[part 2 of 2: package /MICROSAR/Dcm_swc/ComponentTypes]
AUTOSAR XML (schema 00048)
package /MICROSAR/Dcm_swc/ComponentTypes
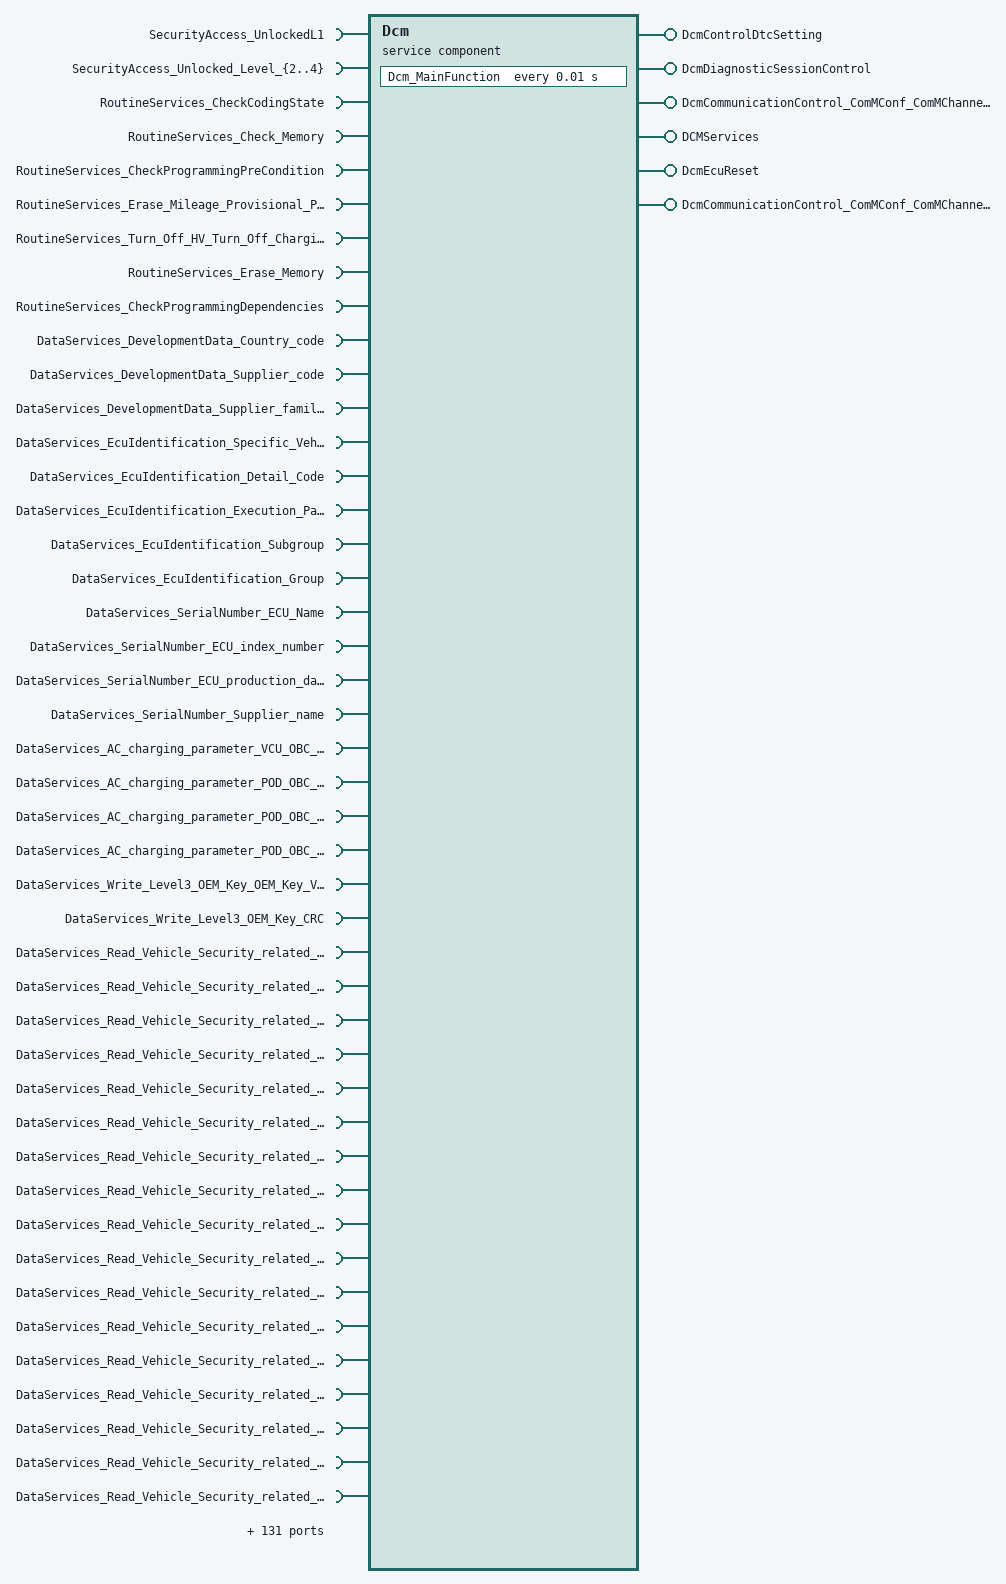
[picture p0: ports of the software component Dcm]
  service sw component type Dcm: category=SERVICE_COMPONENT
    4 x provide port:
      DcmControlDtcSetting: provided-interface=DcmControlDtcSetting
      DcmDiagnosticSessionControl: provided-interface=DcmDiagnosticSessionControl
      DcmCommunicationControl_ComMConf_ComMChannel_CN_TC37X_VCU_CAN00_07b6c9c8: provided-interface=DcmCommunicationControl_ComMConf_ComMChannel_CN_TC37X_VCU_CAN00_07b6c9c8
      DCMServices: provided-interface=DCMServices
    require port SecurityAccess_UnlockedL1: required-interface=SecurityAccess_UnlockedL1
    provide port DcmEcuReset: mode-switch-sender-com-spec{mode-group=DcmEcuReset, mode-switched-ack=timeout=0}, provided-interface=DcmEcuReset
    provide port DcmCommunicationControl_ComMConf_ComMChannel_CN_ATOM_CAN_Matrix_PT_V600_20250211_9b894f3d: provided-interface=DcmCommunicationControl_ComMConf_ComMChannel_CN_ATOM_CAN_Matrix_PT_V600_20250211_9b894f3d
    181 x require port:
      SecurityAccess_Unlocked_Level_{2..4}: required-interface=SecurityAccess_Unlocked_Level_{2..4}
      RoutineServices_CheckCodingState: required-interface=RoutineServices_CheckCodingState
      RoutineServices_Check_Memory: required-interface=RoutineServices_Check_Memory
      RoutineServices_CheckProgrammingPreCondition: required-interface=RoutineServices_CheckProgrammingPreCondition
      RoutineServices_Erase_Mileage_Provisional_Parameter: required-interface=RoutineServices_Erase_Mileage_Provisional_Parameter
      RoutineServices_Turn_Off_HV_Turn_Off_Charging: required-interface=RoutineServices_Turn_Off_HV_Turn_Off_Charging
      RoutineServices_Erase_Memory: required-interface=RoutineServices_Erase_Memory
      RoutineServices_CheckProgrammingDependencies: required-interface=RoutineServices_CheckProgrammingDependencies
      DataServices_DevelopmentData_Country_code: required-interface=DataServices_DevelopmentData_Country_code
      DataServices_DevelopmentData_Supplier_code: required-interface=DataServices_DevelopmentData_Supplier_code
      DataServices_DevelopmentData_Supplier_family_code: required-interface=DataServices_DevelopmentData_Supplier_family_code
      DataServices_EcuIdentification_Specific_Vehicle_Code_WMI: required-interface=DataServices_EcuIdentification_Specific_Vehicle_Code_WMI
      DataServices_EcuIdentification_Detail_Code: required-interface=DataServices_EcuIdentification_Detail_Code
      DataServices_EcuIdentification_Execution_Package: required-interface=DataServices_EcuIdentification_Execution_Package
      DataServices_EcuIdentification_Subgroup: required-interface=DataServices_EcuIdentification_Subgroup
      DataServices_EcuIdentification_Group: required-interface=DataServices_EcuIdentification_Group
      DataServices_SerialNumber_ECU_Name: required-interface=DataServices_SerialNumber_ECU_Name
      DataServices_SerialNumber_ECU_index_number: required-interface=DataServices_SerialNumber_ECU_index_number
      DataServices_SerialNumber_ECU_production_date_in_DD_MM_YY_format: required-interface=DataServices_SerialNumber_ECU_production_date_in_DD_MM_YY_format
      DataServices_SerialNumber_Supplier_name: required-interface=DataServices_SerialNumber_Supplier_name
      DataServices_AC_charging_parameter_VCU_OBC_ChargeCurrentCommand: required-interface=DataServices_AC_charging_parameter_VCU_OBC_ChargeCurrentCommand
      DataServices_AC_charging_parameter_POD_OBC_InputACVoltage: required-interface=DataServices_AC_charging_parameter_POD_OBC_InputACVoltage
      DataServices_AC_charging_parameter_POD_OBC_OutputDCChargeVoltage: required-interface=DataServices_AC_charging_parameter_POD_OBC_OutputDCChargeVoltage
      DataServices_AC_charging_parameter_POD_OBC_OutputDCChargeCurrent: required-interface=DataServices_AC_charging_parameter_POD_OBC_OutputDCChargeCurrent
      DataServices_Write_Level3_OEM_Key_OEM_Key_Value: required-interface=DataServices_Write_Level3_OEM_Key_OEM_Key_Value
      DataServices_Write_Level3_OEM_Key_CRC: required-interface=DataServices_Write_Level3_OEM_Key_CRC
      DataServices_Read_Vehicle_Security_related_events_Software_configuration_inte_Event_occurance_time_Year_1: required-interface=DataServices_Read_Vehicle_Security_related_events_Software_configuration_inte_Event_occurance_time_Year_1
      DataServices_Read_Vehicle_Security_related_events_Software_configuration_inte_Event_occurance_time_Day_1: required-interface=DataServices_Read_Vehicle_Security_related_events_Software_configuration_inte_Event_occurance_time_Day_1
      DataServices_Read_Vehicle_Security_related_events_Software_configuration_inte_Software_configuration_integrity_check_fa_B04CEA39: required-interface=DataServices_Read_Vehicle_Security_related_events_Software_configuration_inte_Software_configuration_integrity_check_fa_B04CEA39
      DataServices_Read_Vehicle_Security_related_events_Software_configuration_inte_Event_occurance_time_Day_{2..5}: required-interface=DataServices_Read_Vehicle_Security_related_events_Software_configuration_inte_Event_occurance_time_Day_{2..5}
      DataServices_Read_Vehicle_Security_related_events_Software_configuration_inte_Software_configuration_integrity_check_5: required-interface=DataServices_Read_Vehicle_Security_related_events_Software_configuration_inte_Software_configuration_integrity_check_5
      DataServices_Read_Vehicle_Security_related_events_Software_configuration_inte_Event_occurance_time_Month_2: required-interface=DataServices_Read_Vehicle_Security_related_events_Software_configuration_inte_Event_occurance_time_Month_2
      DataServices_Read_Vehicle_Security_related_events_Software_configuration_inte_Event_occurance_time_Month_1: required-interface=DataServices_Read_Vehicle_Security_related_events_Software_configuration_inte_Event_occurance_time_Month_1
      DataServices_Read_Vehicle_Security_related_events_Software_configuration_inte_Event_occurance_time_Month_4: required-interface=DataServices_Read_Vehicle_Security_related_events_Software_configuration_inte_Event_occurance_time_Month_4
      DataServices_Read_Vehicle_Security_related_events_Software_configuration_inte_Software_configuration_integrity_check_3: required-interface=DataServices_Read_Vehicle_Security_related_events_Software_configuration_inte_Software_configuration_integrity_check_3
      DataServices_Read_Vehicle_Security_related_events_Software_configuration_inte_Software_configuration_integrity_check_4: required-interface=DataServices_Read_Vehicle_Security_related_events_Software_configuration_inte_Software_configuration_integrity_check_4
      DataServices_Read_Vehicle_Security_related_events_Software_configuration_inte_Event_occurance_time_Month_3: required-interface=DataServices_Read_Vehicle_Security_related_events_Software_configuration_inte_Event_occurance_time_Month_3
      DataServices_Read_Vehicle_Security_related_events_Software_configuration_inte_Software_configuration_integrity_check_1: required-interface=DataServices_Read_Vehicle_Security_related_events_Software_configuration_inte_Software_configuration_integrity_check_1
      DataServices_Read_Vehicle_Security_related_events_Software_configuration_inte_Event_occurance_time_Month_5: required-interface=DataServices_Read_Vehicle_Security_related_events_Software_configuration_inte_Event_occurance_time_Month_5
      DataServices_Read_Vehicle_Security_related_events_Software_configuration_inte_Software_configuration_integrity_check_2: required-interface=DataServices_Read_Vehicle_Security_related_events_Software_configuration_inte_Software_configuration_integrity_check_2
      DataServices_Read_Vehicle_Security_related_events_Software_configuration_inte_Event_occurance_time_Year_4: required-interface=DataServices_Read_Vehicle_Security_related_events_Software_configuration_inte_Event_occurance_time_Year_4
      DataServices_Read_Vehicle_Security_related_events_Software_configuration_inte_Event_occurance_time_Year_5: required-interface=DataServices_Read_Vehicle_Security_related_events_Software_configuration_inte_Event_occurance_time_Year_5
      DataServices_Read_Vehicle_Security_related_events_Software_configuration_inte_Event_occurance_time_Year_2: required-interface=DataServices_Read_Vehicle_Security_related_events_Software_configuration_inte_Event_occurance_time_Year_2
      DataServices_Read_Vehicle_Security_related_events_Software_configuration_inte_Event_occurance_time_Year_3: required-interface=DataServices_Read_Vehicle_Security_related_events_Software_configuration_inte_Event_occurance_time_Year_3
      DataServices_BS_base_information4_SOF_V2: required-interface=DataServices_BS_base_information4_SOF_V2
      DataServices_BS_base_information4_VCU_BS_Hcurrent: required-interface=DataServices_BS_base_information4_VCU_BS_Hcurrent
      DataServices_BS_base_information4_SOF_V1: required-interface=DataServices_BS_base_information4_SOF_V1
      DataServices_BS_base_information4_SOH: required-interface=DataServices_BS_base_information4_SOH
      DataServices_BS_base_information4_BS_SOC: required-interface=DataServices_BS_base_information4_BS_SOC
      DataServices_BS_base_information4_T_BATT: required-interface=DataServices_BS_base_information4_T_BATT
      DataServices_Read_Level4_OEM_Key_written_status_Read_Level4_OEM_Key_rewrite_counter: required-interface=DataServices_Read_Level4_OEM_Key_written_status_Read_Level4_OEM_Key_rewrite_counter
      DataServices_Read_active_diagnostic_session_Active_diagnostic_session: required-interface=DataServices_Read_active_diagnostic_session_Active_diagnostic_session
      DataServices_Total_Odometer_VCU_Total_Odometer_VCU: required-interface=DataServices_Total_Odometer_VCU_Total_Odometer_VCU
      DataServices_VCU_HVStatus_VCU_HVStatus: required-interface=DataServices_VCU_HVStatus_VCU_HVStatus
      DataServices_Vehicle_speed_Vehicle_speed: required-interface=DataServices_Vehicle_speed_Vehicle_speed
      DataServices_Read_ECU_manufacturing_date_ECU_Manufacturing_Date_Day: required-interface=DataServices_Read_ECU_manufacturing_date_ECU_Manufacturing_Date_Day
      DataServices_Read_ECU_manufacturing_date_ECU_Manufacturing_Date_Month: required-interface=DataServices_Read_ECU_manufacturing_date_ECU_Manufacturing_Date_Month
      DataServices_Read_ECU_manufacturing_date_ECU_Manufacturing_Date_Year: required-interface=DataServices_Read_ECU_manufacturing_date_ECU_Manufacturing_Date_Year
      DataServices_HV_Status_and_Charging_Status_HV_status_and_charging_status: required-interface=DataServices_HV_Status_and_Charging_Status_HV_status_and_charging_status
      DataServices_SOC_SOC: required-interface=DataServices_SOC_SOC
      DataServices_Supplier_ECU_hardware_part_number_Major_release: required-interface=DataServices_Supplier_ECU_hardware_part_number_Major_release
      DataServices_Supplier_ECU_hardware_part_number_Changes_in_electronic_components_level: required-interface=DataServices_Supplier_ECU_hardware_part_number_Changes_in_electronic_components_level
      DataServices_Write_Level4_OEM_Key_OEM_Key_Value: required-interface=DataServices_Write_Level4_OEM_Key_OEM_Key_Value
      DataServices_Write_Level4_OEM_Key_CRC: required-interface=DataServices_Write_Level4_OEM_Key_CRC
      DataServices_VCU_AccPealparameter_VCU_AccelerationPedal: required-interface=DataServices_VCU_AccPealparameter_VCU_AccelerationPedal
      DataServices_VCU_AccPealparameter_Accelerator_pedal_sensor_2_voltage: required-interface=DataServices_VCU_AccPealparameter_Accelerator_pedal_sensor_2_voltage
      DataServices_VCU_AccPealparameter_Accelerator_pedal_sensor_1_voltage: required-interface=DataServices_VCU_AccPealparameter_Accelerator_pedal_sensor_1_voltage
      DataServices_VCU_AccPealparameter_VCU_VehicleSpeed: required-interface=DataServices_VCU_AccPealparameter_VCU_VehicleSpeed
      DataServices_HV_part_work_mode_HV_part_work_mode1: required-interface=DataServices_HV_part_work_mode_HV_part_work_mode1
      DataServices_HV_part_work_mode_HV_part_work_mode2: required-interface=DataServices_HV_part_work_mode_HV_part_work_mode2
      DataServices_Bootloader_version_number_Major_release: required-interface=DataServices_Bootloader_version_number_Major_release
      DataServices_Bootloader_version_number_Minor_release: required-interface=DataServices_Bootloader_version_number_Minor_release
      DataServices_Bootloader_version_number_No_functional_content_change: required-interface=DataServices_Bootloader_version_number_No_functional_content_change
      DataServices_Read_Level1_OEM_Key_written_status_Read_Level1_OEM_Key_rewrite_counter: required-interface=DataServices_Read_Level1_OEM_Key_written_status_Read_Level1_OEM_Key_rewrite_counter
      DataServices_Coding_for_CDS_fingerprint_codingDate_byte_3_DD: required-interface=DataServices_Coding_for_CDS_fingerprint_codingDate_byte_3_DD
      DataServices_Coding_for_CDS_fingerprint_codingDate_byte_2_MM: required-interface=DataServices_Coding_for_CDS_fingerprint_codingDate_byte_2_MM
      DataServices_Coding_for_CDS_fingerprint_codingDate_byte_1_YY: required-interface=DataServices_Coding_for_CDS_fingerprint_codingDate_byte_1_YY
      DataServices_Coding_for_CDS_fingerprint_repairShopCodeorTesterSerialNumber_byte_1_27_MSB: required-interface=DataServices_Coding_for_CDS_fingerprint_repairShopCodeorTesterSerialNumber_byte_1_27_MSB
      DataServices_VCU_control_main_relay_Mainrealy1: required-interface=DataServices_VCU_control_main_relay_Mainrealy1
      DataServices_VCU_control_main_relay_Mainrelay2: required-interface=DataServices_VCU_control_main_relay_Mainrelay2
      DataServices_VCU_control_S2_status_New_Bit_Field: required-interface=DataServices_VCU_control_S2_status_New_Bit_Field
      DataServices_Electronic_lock_state_Electronic_lock_state: required-interface=DataServices_Electronic_lock_state_Electronic_lock_state
      DataServices_DC_Charging_port_Temperature_POD_DCInletTempA: required-interface=DataServices_DC_Charging_port_Temperature_POD_DCInletTempA
      DataServices_DC_Charging_port_Temperature_POD_DCInletTempB: required-interface=DataServices_DC_Charging_port_Temperature_POD_DCInletTempB
      DataServices_Total_Odometer_Total_Odometer: required-interface=DataServices_Total_Odometer_Total_Odometer
      DataServices_VCU_HV_InterLock_PWM_pfrequency_VCU_HVIL: required-interface=DataServices_VCU_HV_InterLock_PWM_pfrequency_VCU_HVIL
      DataServices_PWT_vehicle_fault_PWT_ErrorLevel{1..3}: required-interface=DataServices_PWT_vehicle_fault_PWT_ErrorLevel{1..3}
      DataServices_VCU_PowerMaxAllowed_parameter1_VCU_DisChgPowerLimit: required-interface=DataServices_VCU_PowerMaxAllowed_parameter1_VCU_DisChgPowerLimit
      DataServices_VCU_PowerMaxAllowed_parameter1_VCU_TCUPowerAllowed: required-interface=DataServices_VCU_PowerMaxAllowed_parameter1_VCU_TCUPowerAllowed
      DataServices_VCU_PowerMaxAllowed_parameter1_VCU_DCDCPowerLimit: required-interface=DataServices_VCU_PowerMaxAllowed_parameter1_VCU_DCDCPowerLimit
      DataServices_VCU_PowerMaxAllowed_parameter1_MCUPowerLimit: required-interface=DataServices_VCU_PowerMaxAllowed_parameter1_MCUPowerLimit
      DataServices_VCU_PowerMaxAllowed_parameter2_BMSChgPowerLimit: required-interface=DataServices_VCU_PowerMaxAllowed_parameter2_BMSChgPowerLimit
      DataServices_VCU_PowerMaxAllowed_parameter2_MCUFeedbackPowerLimit: required-interface=DataServices_VCU_PowerMaxAllowed_parameter2_MCUFeedbackPowerLimit
      DataServices_VCU_PowerMaxAllowed_parameter2_BMSDisChgPowerLimit: required-interface=DataServices_VCU_PowerMaxAllowed_parameter2_BMSDisChgPowerLimit
      DataServices_VCU_PowerMaxAllowed_parameter3_ACSystemPower: required-interface=DataServices_VCU_PowerMaxAllowed_parameter3_ACSystemPower
      DataServices_VCU_PowerMaxAllowed_parameter3_V2LPower: required-interface=DataServices_VCU_PowerMaxAllowed_parameter3_V2LPower
      DataServices_VCU_PowerMaxAllowed_parameter3_PackPTCPower: required-interface=DataServices_VCU_PowerMaxAllowed_parameter3_PackPTCPower
      DataServices_VCU_PowerMaxAllowed_parameter3_MCUPower: required-interface=DataServices_VCU_PowerMaxAllowed_parameter3_MCUPower
      DataServices_VCU_PowerMaxAllowed_parameter3_DCDCPower: required-interface=DataServices_VCU_PowerMaxAllowed_parameter3_DCDCPower
      DataServices_Gear_Gear: required-interface=DataServices_Gear_Gear
      DataServices_Chargestatus_Chargestatus: required-interface=DataServices_Chargestatus_Chargestatus
      DataServices_Read_Level2_OEM_Key_written_status_Read_Level2_OEM_Key_rewrite_counter: required-interface=DataServices_Read_Level2_OEM_Key_written_status_Read_Level2_OEM_Key_rewrite_counter
      DataServices_Vehicle_State_Ignition_Switch_Signal: required-interface=DataServices_Vehicle_State_Ignition_Switch_Signal
      DataServices_Read_ECU_Part_Number_Specific_Vehicle_Code_WMI: required-interface=DataServices_Read_ECU_Part_Number_Specific_Vehicle_Code_WMI
      DataServices_Read_ECU_Part_Number_Detail_Code: required-interface=DataServices_Read_ECU_Part_Number_Detail_Code
      DataServices_Read_ECU_Part_Number_Execution_Package: required-interface=DataServices_Read_ECU_Part_Number_Execution_Package
      DataServices_Read_ECU_Part_Number_Subgroup: required-interface=DataServices_Read_ECU_Part_Number_Subgroup
      DataServices_Read_ECU_Part_Number_Group: required-interface=DataServices_Read_ECU_Part_Number_Group
      DataServices_Write_Level2_OEM_Key_OEM_Key_Value: required-interface=DataServices_Write_Level2_OEM_Key_OEM_Key_Value
      DataServices_Write_Level2_OEM_Key_CRC: required-interface=DataServices_Write_Level2_OEM_Key_CRC
      DataServices_BSW_version_number_Major_release: required-interface=DataServices_BSW_version_number_Major_release
      DataServices_BSW_version_number_Minor_release: required-interface=DataServices_BSW_version_number_Minor_release
      DataServices_BSW_version_number_No_functional_content_change: required-interface=DataServices_BSW_version_number_No_functional_content_change
      DataServices_Read_Vehicle_Security_related_events_Brute_Force_UDS_0x27_servic_Event_occurance_time_Year_1: required-interface=DataServices_Read_Vehicle_Security_related_events_Brute_Force_UDS_0x27_servic_Event_occurance_time_Year_1
      DataServices_Read_Vehicle_Security_related_events_Brute_Force_UDS_0x27_servic_Brute_Force_UDS_0x27_service_Event_occurr_0DEE2FAA: required-interface=DataServices_Read_Vehicle_Security_related_events_Brute_Force_UDS_0x27_servic_Brute_Force_UDS_0x27_service_Event_occurr_0DEE2FAA
      DataServices_Read_Vehicle_Security_related_events_Brute_Force_UDS_0x27_servic_Event_occurance_time_Day_1: required-interface=DataServices_Read_Vehicle_Security_related_events_Brute_Force_UDS_0x27_servic_Event_occurance_time_Day_1
      DataServices_Read_Vehicle_Security_related_events_Brute_Force_UDS_0x27_servic_Event_occurance_time_Day_2: required-interface=DataServices_Read_Vehicle_Security_related_events_Brute_Force_UDS_0x27_servic_Event_occurance_time_Day_2
      DataServices_Read_Vehicle_Security_related_events_Brute_Force_UDS_0x27_servic_Brute_Force_UDS_0x27_service_4: required-interface=DataServices_Read_Vehicle_Security_related_events_Brute_Force_UDS_0x27_servic_Brute_Force_UDS_0x27_service_4
      DataServices_Read_Vehicle_Security_related_events_Brute_Force_UDS_0x27_servic_Event_occurance_time_Day_3: required-interface=DataServices_Read_Vehicle_Security_related_events_Brute_Force_UDS_0x27_servic_Event_occurance_time_Day_3
      DataServices_Read_Vehicle_Security_related_events_Brute_Force_UDS_0x27_servic_Event_occurance_time_Day_4: required-interface=DataServices_Read_Vehicle_Security_related_events_Brute_Force_UDS_0x27_servic_Event_occurance_time_Day_4
      DataServices_Read_Vehicle_Security_related_events_Brute_Force_UDS_0x27_servic_Brute_Force_UDS_0x27_service_3: required-interface=DataServices_Read_Vehicle_Security_related_events_Brute_Force_UDS_0x27_servic_Brute_Force_UDS_0x27_service_3
      DataServices_Read_Vehicle_Security_related_events_Brute_Force_UDS_0x27_servic_Event_occurance_time_Day_5: required-interface=DataServices_Read_Vehicle_Security_related_events_Brute_Force_UDS_0x27_servic_Event_occurance_time_Day_5
      DataServices_Read_Vehicle_Security_related_events_Brute_Force_UDS_0x27_servic_Event_occurance_time_Month_2: required-interface=DataServices_Read_Vehicle_Security_related_events_Brute_Force_UDS_0x27_servic_Event_occurance_time_Month_2
      DataServices_Read_Vehicle_Security_related_events_Brute_Force_UDS_0x27_servic_Brute_Force_UDS_0x27_service_5: required-interface=DataServices_Read_Vehicle_Security_related_events_Brute_Force_UDS_0x27_servic_Brute_Force_UDS_0x27_service_5
      DataServices_Read_Vehicle_Security_related_events_Brute_Force_UDS_0x27_servic_Event_occurance_time_Month_1: required-interface=DataServices_Read_Vehicle_Security_related_events_Brute_Force_UDS_0x27_servic_Event_occurance_time_Month_1
      DataServices_Read_Vehicle_Security_related_events_Brute_Force_UDS_0x27_servic_Event_occurance_time_Month_4: required-interface=DataServices_Read_Vehicle_Security_related_events_Brute_Force_UDS_0x27_servic_Event_occurance_time_Month_4
      DataServices_Read_Vehicle_Security_related_events_Brute_Force_UDS_0x27_servic_Event_occurance_time_Month_3: required-interface=DataServices_Read_Vehicle_Security_related_events_Brute_Force_UDS_0x27_servic_Event_occurance_time_Month_3
      DataServices_Read_Vehicle_Security_related_events_Brute_Force_UDS_0x27_servic_Event_occurance_time_Month_5: required-interface=DataServices_Read_Vehicle_Security_related_events_Brute_Force_UDS_0x27_servic_Event_occurance_time_Month_5
      DataServices_Read_Vehicle_Security_related_events_Brute_Force_UDS_0x27_servic_Event_occurance_time_Year_4: required-interface=DataServices_Read_Vehicle_Security_related_events_Brute_Force_UDS_0x27_servic_Event_occurance_time_Year_4
      DataServices_Read_Vehicle_Security_related_events_Brute_Force_UDS_0x27_servic_Event_occurance_time_Year_5: required-interface=DataServices_Read_Vehicle_Security_related_events_Brute_Force_UDS_0x27_servic_Event_occurance_time_Year_5
      DataServices_Read_Vehicle_Security_related_events_Brute_Force_UDS_0x27_servic_Event_occurance_time_Year_2: required-interface=DataServices_Read_Vehicle_Security_related_events_Brute_Force_UDS_0x27_servic_Event_occurance_time_Year_2
      DataServices_Read_Vehicle_Security_related_events_Brute_Force_UDS_0x27_servic_Event_occurance_time_Year_3: required-interface=DataServices_Read_Vehicle_Security_related_events_Brute_Force_UDS_0x27_servic_Event_occurance_time_Year_3
      DataServices_Read_Vehicle_Security_related_events_Brute_Force_UDS_0x27_servic_Brute_Force_UDS_0x27_service_2: required-interface=DataServices_Read_Vehicle_Security_related_events_Brute_Force_UDS_0x27_servic_Brute_Force_UDS_0x27_service_2
      DataServices_Read_Vehicle_Security_related_events_Brute_Force_UDS_0x27_servic_Brute_Force_UDS_0x27_service_1: required-interface=DataServices_Read_Vehicle_Security_related_events_Brute_Force_UDS_0x27_servic_Brute_Force_UDS_0x27_service_1
      DataServices_Driver_Mode_Driver_Mode: required-interface=DataServices_Driver_Mode_Driver_Mode
      DataServices_Battery_Voltage_Battery_Voltage: required-interface=DataServices_Battery_Voltage_Battery_Voltage
      DataServices_Read_Write_coding_data_string_CDS_CDS_Short_VIN_High_Byte_7: required-interface=DataServices_Read_Write_coding_data_string_CDS_CDS_Short_VIN_High_Byte_7
      DataServices_Read_Write_coding_data_string_CDS_CDS_CRC: required-interface=DataServices_Read_Write_coding_data_string_CDS_CDS_CRC
      DataServices_Read_Write_coding_data_string_CDS_CDS_Format_Byte_High_Byte_0: required-interface=DataServices_Read_Write_coding_data_string_CDS_CDS_Format_Byte_High_Byte_0
      DataServices_Read_Write_coding_data_string_CDS_CDS_Format_Byte_High_Byte_1: required-interface=DataServices_Read_Write_coding_data_string_CDS_CDS_Format_Byte_High_Byte_1
      DataServices_Read_Write_coding_data_string_CDS_Reserved2: required-interface=DataServices_Read_Write_coding_data_string_CDS_Reserved2
      DataServices_Read_Write_coding_data_string_CDS_Version_Byte_0: required-interface=DataServices_Read_Write_coding_data_string_CDS_Version_Byte_0
      DataServices_Read_Write_coding_data_string_CDS_Reserved1: required-interface=DataServices_Read_Write_coding_data_string_CDS_Reserved1
      DataServices_Read_Write_coding_data_string_CDS_Reserved3: required-interface=DataServices_Read_Write_coding_data_string_CDS_Reserved3
      DataServices_Read_Write_coding_data_string_CDS_Version_Byte_1: required-interface=DataServices_Read_Write_coding_data_string_CDS_Version_Byte_1
      DataServices_Read_Write_coding_data_string_CDS_CDS_Short_VIN_High_Byte_4: required-interface=DataServices_Read_Write_coding_data_string_CDS_CDS_Short_VIN_High_Byte_4
      DataServices_Read_Write_coding_data_string_CDS_Configuration: required-interface=DataServices_Read_Write_coding_data_string_CDS_Configuration
      DataServices_Read_Write_coding_data_string_CDS_CDS_Short_VIN_High_Byte_3: required-interface=DataServices_Read_Write_coding_data_string_CDS_CDS_Short_VIN_High_Byte_3
      DataServices_Read_Write_coding_data_string_CDS_CDS_Short_VIN_High_Byte_5: required-interface=DataServices_Read_Write_coding_data_string_CDS_CDS_Short_VIN_High_Byte_5
      DataServices_Read_Write_coding_data_string_CDS_CDS_Short_VIN_High_Byte_0: required-interface=DataServices_Read_Write_coding_data_string_CDS_CDS_Short_VIN_High_Byte_0
      DataServices_Read_Write_coding_data_string_CDS_CDS_Short_VIN_High_Byte_2: required-interface=DataServices_Read_Write_coding_data_string_CDS_CDS_Short_VIN_High_Byte_2
      DataServices_Read_Write_coding_data_string_CDS_CDS_Short_VIN_High_Byte_1: required-interface=DataServices_Read_Write_coding_data_string_CDS_CDS_Short_VIN_High_Byte_1
      DataServices_Last_service_date_Day: required-interface=DataServices_Last_service_date_Day
      DataServices_Last_service_date_Month: required-interface=DataServices_Last_service_date_Month
      DataServices_Last_service_date_Year: required-interface=DataServices_Last_service_date_Year
      DataServices_Date_And_Time_Date_And_Time_Minute: required-interface=DataServices_Date_And_Time_Date_And_Time_Minute
      DataServices_Date_And_Time_Date_And_Time_Hour: required-interface=DataServices_Date_And_Time_Date_And_Time_Hour
      DataServices_Date_And_Time_Date_And_Time_Year: required-interface=DataServices_Date_And_Time_Date_And_Time_Year
      DataServices_Date_And_Time_Date_And_Time_Second: required-interface=DataServices_Date_And_Time_Date_And_Time_Second
      DataServices_Date_And_Time_Date_And_Time_Month: required-interface=DataServices_Date_And_Time_Date_And_Time_Month
      DataServices_Date_And_Time_Date_And_Time_Day: required-interface=DataServices_Date_And_Time_Date_And_Time_Day
      DataServices_VCU_Torque_parameter_VCU_RegenTorqueCap: required-interface=DataServices_VCU_Torque_parameter_VCU_RegenTorqueCap
      DataServices_VCU_Torque_parameter_Torque_MaxAllowed: required-interface=DataServices_VCU_Torque_parameter_Torque_MaxAllowed
      DataServices_VCU_Torque_parameter_VCU_MCUDesiredTorque: required-interface=DataServices_VCU_Torque_parameter_VCU_MCUDesiredTorque
      DataServices_VCU_Torque_parameter_Torque_MinAllowed: required-interface=DataServices_VCU_Torque_parameter_Torque_MinAllowed
      DataServices_ECU_application_software_ASW_version_number_Major_release: required-interface=DataServices_ECU_application_software_ASW_version_number_Major_release
      DataServices_ECU_application_software_ASW_version_number_Minor_release: required-interface=DataServices_ECU_application_software_ASW_version_number_Minor_release
      DataServices_ECU_application_software_ASW_version_number_No_functional_content_change: required-interface=DataServices_ECU_application_software_ASW_version_number_No_functional_content_change
      DataServices_Read_Level3_OEM_Key_written_status_Read_Level3_OEM_Key_rewrite_counter: required-interface=DataServices_Read_Level3_OEM_Key_written_status_Read_Level3_OEM_Key_rewrite_counter
      DataServices_Write_Level1_OEM_Key_OEM_Key_Value: required-interface=DataServices_Write_Level1_OEM_Key_OEM_Key_Value
      DataServices_Write_Level1_OEM_Key_CRC: required-interface=DataServices_Write_Level1_OEM_Key_CRC
      DataServices_Read_Write_complete_VIN_World_Manufacturers_Identification: required-interface=DataServices_Read_Write_complete_VIN_World_Manufacturers_Identification
      DataServices_Read_Write_complete_VIN_Vehicle_Description_Section: required-interface=DataServices_Read_Write_complete_VIN_Vehicle_Description_Section
      DataServices_Read_Write_complete_VIN_Vehicle_Identification_Section: required-interface=DataServices_Read_Write_complete_VIN_Vehicle_Identification_Section
    behavior DcmInternalBehavior: data-type-mapping=DcmMappingSet, handle-termination-and-restart=NO-SUPPORT, included-data-type-set=data-type=[Dcm_ConfirmationStatusType, Dcm_OpStatusType, Dcm_NegativeResponseCodeType, Dcm_ProtocolType, Dcm_RequestKindType, Dcm_SecLevelType, Dcm_SesCtrlType, Dcm_ControlDtcSettingType, Dcm_EcuResetType, Dcm_DiagnosticSessionControlType, Dcm_CommunicationModeType]
      timing event Timer_Dcm_MainFunction: start-on-event=Dcm_MainFunction, period=0.01
      6 x operation invoked event:
        OpEventGetActiveProtocol_GetActiveProtocol_DCMServices: start-on-event=GetActiveProtocol, operation=DCMServices.GetActiveProtocol
        OpEventGetSesCtrlType_GetSesCtrlType_DCMServices: start-on-event=GetSesCtrlType, operation=DCMServices.GetSesCtrlType
        OpEventResetToDefaultSession_ResetToDefaultSession_DCMServices: start-on-event=ResetToDefaultSession, operation=DCMServices.ResetToDefaultSession
        OpEventGetSecurityLevel_GetSecurityLevel_DCMServices: start-on-event=GetSecurityLevel, operation=DCMServices.GetSecurityLevel
        OpEventSetActiveDiagnostic_SetActiveDiagnostic_DCMServices: start-on-event=SetActiveDiagnostic, operation=DCMServices.SetActiveDiagnostic
        OpEventGetRequestKind_GetRequestKind_DCMServices: start-on-event=GetRequestKind, operation=DCMServices.GetRequestKind
      port-api-options:
        enable-take-address=true, indirect-api=false, port=DcmControlDtcSetting
        enable-take-address=true, indirect-api=false, port=DcmEcuReset
        enable-take-address=true, indirect-api=false, port=DcmDiagnosticSessionControl
        enable-take-address=true, indirect-api=false, port=DcmCommunicationControl_ComMConf_ComMChannel_CN_TC37X_VCU_CAN00_07b6c9c8
        enable-take-address=true, indirect-api=false, port=DCMServices
        enable-take-address=true, indirect-api=false, port=SecurityAccess_UnlockedL1
        enable-take-address=true, indirect-api=false, port=DcmCommunicationControl_ComMConf_ComMChannel_CN_ATOM_CAN_Matrix_PT_V600_20250211_9b894f3d
        enable-take-address=true, indirect-api=false, port=SecurityAccess_Unlocked_Level_{2..4}
        enable-take-address=true, indirect-api=false, port=RoutineServices_CheckCodingState
        enable-take-address=true, indirect-api=false, port=RoutineServices_Check_Memory
        enable-take-address=true, indirect-api=false, port=RoutineServices_CheckProgrammingPreCondition
        enable-take-address=true, indirect-api=false, port=RoutineServices_Erase_Mileage_Provisional_Parameter
        enable-take-address=true, indirect-api=false, port=RoutineServices_Turn_Off_HV_Turn_Off_Charging
        enable-take-address=true, indirect-api=false, port=RoutineServices_Erase_Memory
        enable-take-address=true, indirect-api=false, port=RoutineServices_CheckProgrammingDependencies
        enable-take-address=true, indirect-api=false, port=DataServices_DevelopmentData_Country_code
        enable-take-address=true, indirect-api=false, port=DataServices_DevelopmentData_Supplier_code
        enable-take-address=true, indirect-api=false, port=DataServices_DevelopmentData_Supplier_family_code
        enable-take-address=true, indirect-api=false, port=DataServices_EcuIdentification_Specific_Vehicle_Code_WMI
        enable-take-address=true, indirect-api=false, port=DataServices_EcuIdentification_Detail_Code
        enable-take-address=true, indirect-api=false, port=DataServices_EcuIdentification_Execution_Package
        enable-take-address=true, indirect-api=false, port=DataServices_EcuIdentification_Subgroup
        enable-take-address=true, indirect-api=false, port=DataServices_EcuIdentification_Group
        enable-take-address=true, indirect-api=false, port=DataServices_SerialNumber_ECU_Name
        enable-take-address=true, indirect-api=false, port=DataServices_SerialNumber_ECU_index_number
        enable-take-address=true, indirect-api=false, port=DataServices_SerialNumber_ECU_production_date_in_DD_MM_YY_format
        enable-take-address=true, indirect-api=false, port=DataServices_SerialNumber_Supplier_name
        enable-take-address=true, indirect-api=false, port=DataServices_AC_charging_parameter_VCU_OBC_ChargeCurrentCommand
        enable-take-address=true, indirect-api=false, port=DataServices_AC_charging_parameter_POD_OBC_InputACVoltage
        enable-take-address=true, indirect-api=false, port=DataServices_AC_charging_parameter_POD_OBC_OutputDCChargeVoltage
        enable-take-address=true, indirect-api=false, port=DataServices_AC_charging_parameter_POD_OBC_OutputDCChargeCurrent
        enable-take-address=true, indirect-api=false, port=DataServices_Write_Level3_OEM_Key_OEM_Key_Value
        enable-take-address=true, indirect-api=false, port=DataServices_Write_Level3_OEM_Key_CRC
        enable-take-address=true, indirect-api=false, port=DataServices_Read_Vehicle_Security_related_events_Software_configuration_inte_Event_occurance_time_Year_1
        enable-take-address=true, indirect-api=false, port=DataServices_Read_Vehicle_Security_related_events_Software_configuration_inte_Event_occurance_time_Day_1
        enable-take-address=true, indirect-api=false, port=DataServices_Read_Vehicle_Security_related_events_Software_configuration_inte_Software_configuration_integrity_check_fa_B04CEA39
        enable-take-address=true, indirect-api=false, port=DataServices_Read_Vehicle_Security_related_events_Software_configuration_inte_Event_occurance_time_Day_{2..5}
        enable-take-address=true, indirect-api=false, port=DataServices_Read_Vehicle_Security_related_events_Software_configuration_inte_Software_configuration_integrity_check_5
        enable-take-address=true, indirect-api=false, port=DataServices_Read_Vehicle_Security_related_events_Software_configuration_inte_Event_occurance_time_Month_2
        enable-take-address=true, indirect-api=false, port=DataServices_Read_Vehicle_Security_related_events_Software_configuration_inte_Event_occurance_time_Month_1
        enable-take-address=true, indirect-api=false, port=DataServices_Read_Vehicle_Security_related_events_Software_configuration_inte_Event_occurance_time_Month_4
        enable-take-address=true, indirect-api=false, port=DataServices_Read_Vehicle_Security_related_events_Software_configuration_inte_Software_configuration_integrity_check_3
        enable-take-address=true, indirect-api=false, port=DataServices_Read_Vehicle_Security_related_events_Software_configuration_inte_Software_configuration_integrity_check_4
        enable-take-address=true, indirect-api=false, port=DataServices_Read_Vehicle_Security_related_events_Software_configuration_inte_Event_occurance_time_Month_3
        enable-take-address=true, indirect-api=false, port=DataServices_Read_Vehicle_Security_related_events_Software_configuration_inte_Software_configuration_integrity_check_1
        enable-take-address=true, indirect-api=false, port=DataServices_Read_Vehicle_Security_related_events_Software_configuration_inte_Event_occurance_time_Month_5
        enable-take-address=true, indirect-api=false, port=DataServices_Read_Vehicle_Security_related_events_Software_configuration_inte_Software_configuration_integrity_check_2
        enable-take-address=true, indirect-api=false, port=DataServices_Read_Vehicle_Security_related_events_Software_configuration_inte_Event_occurance_time_Year_4
        enable-take-address=true, indirect-api=false, port=DataServices_Read_Vehicle_Security_related_events_Software_configuration_inte_Event_occurance_time_Year_5
        enable-take-address=true, indirect-api=false, port=DataServices_Read_Vehicle_Security_related_events_Software_configuration_inte_Event_occurance_time_Year_2
        enable-take-address=true, indirect-api=false, port=DataServices_Read_Vehicle_Security_related_events_Software_configuration_inte_Event_occurance_time_Year_3
        enable-take-address=true, indirect-api=false, port=DataServices_BS_base_information4_SOF_V2
        enable-take-address=true, indirect-api=false, port=DataServices_BS_base_information4_VCU_BS_Hcurrent
        enable-take-address=true, indirect-api=false, port=DataServices_BS_base_information4_SOF_V1
        enable-take-address=true, indirect-api=false, port=DataServices_BS_base_information4_SOH
        enable-take-address=true, indirect-api=false, port=DataServices_BS_base_information4_BS_SOC
        enable-take-address=true, indirect-api=false, port=DataServices_BS_base_information4_T_BATT
        enable-take-address=true, indirect-api=false, port=DataServices_Read_Level4_OEM_Key_written_status_Read_Level4_OEM_Key_rewrite_counter
        enable-take-address=true, indirect-api=false, port=DataServices_Read_active_diagnostic_session_Active_diagnostic_session
        enable-take-address=true, indirect-api=false, port=DataServices_Total_Odometer_VCU_Total_Odometer_VCU
        enable-take-address=true, indirect-api=false, port=DataServices_VCU_HVStatus_VCU_HVStatus
        enable-take-address=true, indirect-api=false, port=DataServices_Vehicle_speed_Vehicle_speed
        enable-take-address=true, indirect-api=false, port=DataServices_Read_ECU_manufacturing_date_ECU_Manufacturing_Date_Day
        enable-take-address=true, indirect-api=false, port=DataServices_Read_ECU_manufacturing_date_ECU_Manufacturing_Date_Month
        enable-take-address=true, indirect-api=false, port=DataServices_Read_ECU_manufacturing_date_ECU_Manufacturing_Date_Year
        enable-take-address=true, indirect-api=false, port=DataServices_HV_Status_and_Charging_Status_HV_status_and_charging_status
        enable-take-address=true, indirect-api=false, port=DataServices_SOC_SOC
        enable-take-address=true, indirect-api=false, port=DataServices_Supplier_ECU_hardware_part_number_Major_release
        enable-take-address=true, indirect-api=false, port=DataServices_Supplier_ECU_hardware_part_number_Changes_in_electronic_components_level
        enable-take-address=true, indirect-api=false, port=DataServices_Write_Level4_OEM_Key_OEM_Key_Value
        enable-take-address=true, indirect-api=false, port=DataServices_Write_Level4_OEM_Key_CRC
        enable-take-address=true, indirect-api=false, port=DataServices_VCU_AccPealparameter_VCU_AccelerationPedal
        enable-take-address=true, indirect-api=false, port=DataServices_VCU_AccPealparameter_Accelerator_pedal_sensor_2_voltage
        enable-take-address=true, indirect-api=false, port=DataServices_VCU_AccPealparameter_Accelerator_pedal_sensor_1_voltage
        enable-take-address=true, indirect-api=false, port=DataServices_VCU_AccPealparameter_VCU_VehicleSpeed
        enable-take-address=true, indirect-api=false, port=DataServices_HV_part_work_mode_HV_part_work_mode1
        enable-take-address=true, indirect-api=false, port=DataServices_HV_part_work_mode_HV_part_work_mode2
        enable-take-address=true, indirect-api=false, port=DataServices_Bootloader_version_number_Major_release
        enable-take-address=true, indirect-api=false, port=DataServices_Bootloader_version_number_Minor_release
        enable-take-address=true, indirect-api=false, port=DataServices_Bootloader_version_number_No_functional_content_change
        enable-take-address=true, indirect-api=false, port=DataServices_Read_Level1_OEM_Key_written_status_Read_Level1_OEM_Key_rewrite_counter
        enable-take-address=true, indirect-api=false, port=DataServices_Coding_for_CDS_fingerprint_codingDate_byte_3_DD
        enable-take-address=true, indirect-api=false, port=DataServices_Coding_for_CDS_fingerprint_codingDate_byte_2_MM
        enable-take-address=true, indirect-api=false, port=DataServices_Coding_for_CDS_fingerprint_codingDate_byte_1_YY
        enable-take-address=true, indirect-api=false, port=DataServices_Coding_for_CDS_fingerprint_repairShopCodeorTesterSerialNumber_byte_1_27_MSB
        enable-take-address=true, indirect-api=false, port=DataServices_VCU_control_main_relay_Mainrealy1
        enable-take-address=true, indirect-api=false, port=DataServices_VCU_control_main_relay_Mainrelay2
        enable-take-address=true, indirect-api=false, port=DataServices_VCU_control_S2_status_New_Bit_Field
        enable-take-address=true, indirect-api=false, port=DataServices_Electronic_lock_state_Electronic_lock_state
        enable-take-address=true, indirect-api=false, port=DataServices_DC_Charging_port_Temperature_POD_DCInletTempA
        enable-take-address=true, indirect-api=false, port=DataServices_DC_Charging_port_Temperature_POD_DCInletTempB
        enable-take-address=true, indirect-api=false, port=DataServices_Total_Odometer_Total_Odometer
        enable-take-address=true, indirect-api=false, port=DataServices_VCU_HV_InterLock_PWM_pfrequency_VCU_HVIL
        enable-take-address=true, indirect-api=false, port=DataServices_PWT_vehicle_fault_PWT_ErrorLevel{1..3}
        enable-take-address=true, indirect-api=false, port=DataServices_VCU_PowerMaxAllowed_parameter1_VCU_DisChgPowerLimit
        enable-take-address=true, indirect-api=false, port=DataServices_VCU_PowerMaxAllowed_parameter1_VCU_TCUPowerAllowed
        enable-take-address=true, indirect-api=false, port=DataServices_VCU_PowerMaxAllowed_parameter1_VCU_DCDCPowerLimit
        enable-take-address=true, indirect-api=false, port=DataServices_VCU_PowerMaxAllowed_parameter1_MCUPowerLimit
        enable-take-address=true, indirect-api=false, port=DataServices_VCU_PowerMaxAllowed_parameter2_BMSChgPowerLimit
        enable-take-address=true, indirect-api=false, port=DataServices_VCU_PowerMaxAllowed_parameter2_MCUFeedbackPowerLimit
        enable-take-address=true, indirect-api=false, port=DataServices_VCU_PowerMaxAllowed_parameter2_BMSDisChgPowerLimit
        enable-take-address=true, indirect-api=false, port=DataServices_VCU_PowerMaxAllowed_parameter3_ACSystemPower
        enable-take-address=true, indirect-api=false, port=DataServices_VCU_PowerMaxAllowed_parameter3_V2LPower
        enable-take-address=true, indirect-api=false, port=DataServices_VCU_PowerMaxAllowed_parameter3_PackPTCPower
        enable-take-address=true, indirect-api=false, port=DataServices_VCU_PowerMaxAllowed_parameter3_MCUPower
        enable-take-address=true, indirect-api=false, port=DataServices_VCU_PowerMaxAllowed_parameter3_DCDCPower
        enable-take-address=true, indirect-api=false, port=DataServices_Gear_Gear
        enable-take-address=true, indirect-api=false, port=DataServices_Chargestatus_Chargestatus
        enable-take-address=true, indirect-api=false, port=DataServices_Read_Level2_OEM_Key_written_status_Read_Level2_OEM_Key_rewrite_counter
        enable-take-address=true, indirect-api=false, port=DataServices_Vehicle_State_Ignition_Switch_Signal
        enable-take-address=true, indirect-api=false, port=DataServices_Read_ECU_Part_Number_Specific_Vehicle_Code_WMI
        enable-take-address=true, indirect-api=false, port=DataServices_Read_ECU_Part_Number_Detail_Code
        enable-take-address=true, indirect-api=false, port=DataServices_Read_ECU_Part_Number_Execution_Package
        enable-take-address=true, indirect-api=false, port=DataServices_Read_ECU_Part_Number_Subgroup
        enable-take-address=true, indirect-api=false, port=DataServices_Read_ECU_Part_Number_Group
        enable-take-address=true, indirect-api=false, port=DataServices_Write_Level2_OEM_Key_OEM_Key_Value
        enable-take-address=true, indirect-api=false, port=DataServices_Write_Level2_OEM_Key_CRC
        enable-take-address=true, indirect-api=false, port=DataServices_BSW_version_number_Major_release
        enable-take-address=true, indirect-api=false, port=DataServices_BSW_version_number_Minor_release
        enable-take-address=true, indirect-api=false, port=DataServices_BSW_version_number_No_functional_content_change
        enable-take-address=true, indirect-api=false, port=DataServices_Read_Vehicle_Security_related_events_Brute_Force_UDS_0x27_servic_Event_occurance_time_Year_1
        enable-take-address=true, indirect-api=false, port=DataServices_Read_Vehicle_Security_related_events_Brute_Force_UDS_0x27_servic_Brute_Force_UDS_0x27_service_Event_occurr_0DEE2FAA
        enable-take-address=true, indirect-api=false, port=DataServices_Read_Vehicle_Security_related_events_Brute_Force_UDS_0x27_servic_Event_occurance_time_Day_1
        enable-take-address=true, indirect-api=false, port=DataServices_Read_Vehicle_Security_related_events_Brute_Force_UDS_0x27_servic_Event_occurance_time_Day_2
        enable-take-address=true, indirect-api=false, port=DataServices_Read_Vehicle_Security_related_events_Brute_Force_UDS_0x27_servic_Brute_Force_UDS_0x27_service_4
        enable-take-address=true, indirect-api=false, port=DataServices_Read_Vehicle_Security_related_events_Brute_Force_UDS_0x27_servic_Event_occurance_time_Day_3
        enable-take-address=true, indirect-api=false, port=DataServices_Read_Vehicle_Security_related_events_Brute_Force_UDS_0x27_servic_Event_occurance_time_Day_4
        enable-take-address=true, indirect-api=false, port=DataServices_Read_Vehicle_Security_related_events_Brute_Force_UDS_0x27_servic_Brute_Force_UDS_0x27_service_3
        enable-take-address=true, indirect-api=false, port=DataServices_Read_Vehicle_Security_related_events_Brute_Force_UDS_0x27_servic_Event_occurance_time_Day_5
        enable-take-address=true, indirect-api=false, port=DataServices_Read_Vehicle_Security_related_events_Brute_Force_UDS_0x27_servic_Event_occurance_time_Month_2
        enable-take-address=true, indirect-api=false, port=DataServices_Read_Vehicle_Security_related_events_Brute_Force_UDS_0x27_servic_Brute_Force_UDS_0x27_service_5
        enable-take-address=true, indirect-api=false, port=DataServices_Read_Vehicle_Security_related_events_Brute_Force_UDS_0x27_servic_Event_occurance_time_Month_1
        enable-take-address=true, indirect-api=false, port=DataServices_Read_Vehicle_Security_related_events_Brute_Force_UDS_0x27_servic_Event_occurance_time_Month_4
        enable-take-address=true, indirect-api=false, port=DataServices_Read_Vehicle_Security_related_events_Brute_Force_UDS_0x27_servic_Event_occurance_time_Month_3
        enable-take-address=true, indirect-api=false, port=DataServices_Read_Vehicle_Security_related_events_Brute_Force_UDS_0x27_servic_Event_occurance_time_Month_5
        enable-take-address=true, indirect-api=false, port=DataServices_Read_Vehicle_Security_related_events_Brute_Force_UDS_0x27_servic_Event_occurance_time_Year_4
        enable-take-address=true, indirect-api=false, port=DataServices_Read_Vehicle_Security_related_events_Brute_Force_UDS_0x27_servic_Event_occurance_time_Year_5
        enable-take-address=true, indirect-api=false, port=DataServices_Read_Vehicle_Security_related_events_Brute_Force_UDS_0x27_servic_Event_occurance_time_Year_2
        enable-take-address=true, indirect-api=false, port=DataServices_Read_Vehicle_Security_related_events_Brute_Force_UDS_0x27_servic_Event_occurance_time_Year_3
        enable-take-address=true, indirect-api=false, port=DataServices_Read_Vehicle_Security_related_events_Brute_Force_UDS_0x27_servic_Brute_Force_UDS_0x27_service_2
        enable-take-address=true, indirect-api=false, port=DataServices_Read_Vehicle_Security_related_events_Brute_Force_UDS_0x27_servic_Brute_Force_UDS_0x27_service_1
        enable-take-address=true, indirect-api=false, port=DataServices_Driver_Mode_Driver_Mode
        enable-take-address=true, indirect-api=false, port=DataServices_Battery_Voltage_Battery_Voltage
        enable-take-address=true, indirect-api=false, port=DataServices_Read_Write_coding_data_string_CDS_CDS_Short_VIN_High_Byte_7
        enable-take-address=true, indirect-api=false, port=DataServices_Read_Write_coding_data_string_CDS_CDS_CRC
        enable-take-address=true, indirect-api=false, port=DataServices_Read_Write_coding_data_string_CDS_CDS_Format_Byte_High_Byte_0
        enable-take-address=true, indirect-api=false, port=DataServices_Read_Write_coding_data_string_CDS_CDS_Format_Byte_High_Byte_1
        enable-take-address=true, indirect-api=false, port=DataServices_Read_Write_coding_data_string_CDS_Reserved2
        enable-take-address=true, indirect-api=false, port=DataServices_Read_Write_coding_data_string_CDS_Version_Byte_0
        enable-take-address=true, indirect-api=false, port=DataServices_Read_Write_coding_data_string_CDS_Reserved1
        enable-take-address=true, indirect-api=false, port=DataServices_Read_Write_coding_data_string_CDS_Reserved3
        enable-take-address=true, indirect-api=false, port=DataServices_Read_Write_coding_data_string_CDS_Version_Byte_1
        enable-take-address=true, indirect-api=false, port=DataServices_Read_Write_coding_data_string_CDS_CDS_Short_VIN_High_Byte_4
        enable-take-address=true, indirect-api=false, port=DataServices_Read_Write_coding_data_string_CDS_Configuration
        enable-take-address=true, indirect-api=false, port=DataServices_Read_Write_coding_data_string_CDS_CDS_Short_VIN_High_Byte_3
        enable-take-address=true, indirect-api=false, port=DataServices_Read_Write_coding_data_string_CDS_CDS_Short_VIN_High_Byte_5
        enable-take-address=true, indirect-api=false, port=DataServices_Read_Write_coding_data_string_CDS_CDS_Short_VIN_High_Byte_0
        enable-take-address=true, indirect-api=false, port=DataServices_Read_Write_coding_data_string_CDS_CDS_Short_VIN_High_Byte_2
        enable-take-address=true, indirect-api=false, port=DataServices_Read_Write_coding_data_string_CDS_CDS_Short_VIN_High_Byte_1
        enable-take-address=true, indirect-api=false, port=DataServices_Last_service_date_Day
        enable-take-address=true, indirect-api=false, port=DataServices_Last_service_date_Month
        enable-take-address=true, indirect-api=false, port=DataServices_Last_service_date_Year
        enable-take-address=true, indirect-api=false, port=DataServices_Date_And_Time_Date_And_Time_Minute
        enable-take-address=true, indirect-api=false, port=DataServices_Date_And_Time_Date_And_Time_Hour
        enable-take-address=true, indirect-api=false, port=DataServices_Date_And_Time_Date_And_Time_Year
        enable-take-address=true, indirect-api=false, port=DataServices_Date_And_Time_Date_And_Time_Second
        enable-take-address=true, indirect-api=false, port=DataServices_Date_And_Time_Date_And_Time_Month
        enable-take-address=true, indirect-api=false, port=DataServices_Date_And_Time_Date_And_Time_Day
        enable-take-address=true, indirect-api=false, port=DataServices_VCU_Torque_parameter_VCU_RegenTorqueCap
        enable-take-address=true, indirect-api=false, port=DataServices_VCU_Torque_parameter_Torque_MaxAllowed
        enable-take-address=true, indirect-api=false, port=DataServices_VCU_Torque_parameter_VCU_MCUDesiredTorque
        enable-take-address=true, indirect-api=false, port=DataServices_VCU_Torque_parameter_Torque_MinAllowed
        enable-take-address=true, indirect-api=false, port=DataServices_ECU_application_software_ASW_version_number_Major_release
        enable-take-address=true, indirect-api=false, port=DataServices_ECU_application_software_ASW_version_number_Minor_release
        enable-take-address=true, indirect-api=false, port=DataServices_ECU_application_software_ASW_version_number_No_functional_content_change
        enable-take-address=true, indirect-api=false, port=DataServices_Read_Level3_OEM_Key_written_status_Read_Level3_OEM_Key_rewrite_counter
        enable-take-address=true, indirect-api=false, port=DataServices_Write_Level1_OEM_Key_OEM_Key_Value
        enable-take-address=true, indirect-api=false, port=DataServices_Write_Level1_OEM_Key_CRC
        enable-take-address=true, indirect-api=false, port=DataServices_Read_Write_complete_VIN_World_Manufacturers_Identification
        enable-take-address=true, indirect-api=false, port=DataServices_Read_Write_complete_VIN_Vehicle_Description_Section
        enable-take-address=true, indirect-api=false, port=DataServices_Read_Write_complete_VIN_Vehicle_Identification_Section
      7 x runnable:
        Dcm_MainFunction
          5 x mode switch point:
            ModeSwitchPointDcm_MainFunction_DcmControlDtcSetting_DcmControlDtcSetting: mode-group=DcmControlDtcSetting.DcmControlDtcSetting
            ModeSwitchPointDcm_MainFunction_DcmDiagnosticSessionControl_DcmDiagnosticSessionControl: mode-group=DcmDiagnosticSessionControl.DcmDiagnosticSessionControl
            ModeSwitchPointDcm_MainFunction_DcmCommunicationControl_ComMConf_ComMChannel_CN_TC37X_VCU_CAN00_07b6c9c8_DcmCommunicati_215e9f00: mode-group=DcmCommunicationControl_ComMConf_ComMChannel_CN_TC37X_VCU_CAN00_07b6c9c8.DcmCommunicationControl_ComMConf_ComMChannel_CN_TC37X_VCU_CAN00_07b6c9c8
            ModeSwitchPointDcm_MainFunction_DcmEcuReset_DcmEcuReset: mode-group=DcmEcuReset.DcmEcuReset
            ModeSwitchPointDcm_MainFunction_DcmCommunicationControl_ComMConf_ComMChannel_CN_ATOM_CAN_Matrix_PT_V600_20250211_9b894f_c764981a: mode-group=DcmCommunicationControl_ComMConf_ComMChannel_CN_ATOM_CAN_Matrix_PT_V600_20250211_9b894f3d.DcmCommunicationControl_ComMConf_ComMChannel_CN_ATOM_CAN_Matrix_PT_V600_20250211_9b894f3d
          382 x sync call, all with timeout=0:
            OpServerCallDcm_MainFunction_GetSeed_SecurityAccess_UnlockedL1: operation=SecurityAccess_UnlockedL1.GetSeed
            OpServerCallDcm_MainFunction_CompareKey_SecurityAccess_UnlockedL1: operation=SecurityAccess_UnlockedL1.CompareKey
            OpServerCallDcm_MainFunction_GetSeed_SecurityAccess_Unlocked_Level_2: operation=SecurityAccess_Unlocked_Level_2.GetSeed
            OpServerCallDcm_MainFunction_CompareKey_SecurityAccess_Unlocked_Level_2: operation=SecurityAccess_Unlocked_Level_2.CompareKey
            OpServerCallDcm_MainFunction_GetSeed_SecurityAccess_Unlocked_Level_3: operation=SecurityAccess_Unlocked_Level_3.GetSeed
            OpServerCallDcm_MainFunction_CompareKey_SecurityAccess_Unlocked_Level_3: operation=SecurityAccess_Unlocked_Level_3.CompareKey
            OpServerCallDcm_MainFunction_GetSeed_SecurityAccess_Unlocked_Level_4: operation=SecurityAccess_Unlocked_Level_4.GetSeed
            OpServerCallDcm_MainFunction_CompareKey_SecurityAccess_Unlocked_Level_4: operation=SecurityAccess_Unlocked_Level_4.CompareKey
            OpServerCallDcm_MainFunction_Start_RoutineServices_CheckCodingState: operation=RoutineServices_CheckCodingState.Start
            OpServerCallDcm_MainFunction_Start_RoutineServices_Check_Memory: operation=RoutineServices_Check_Memory.Start
            OpServerCallDcm_MainFunction_Start_RoutineServices_CheckProgrammingPreCondition: operation=RoutineServices_CheckProgrammingPreCondition.Start
            OpServerCallDcm_MainFunction_Start_RoutineServices_Erase_Mileage_Provisional_Parameter: operation=RoutineServices_Erase_Mileage_Provisional_Parameter.Start
            OpServerCallDcm_MainFunction_Start_RoutineServices_Turn_Off_HV_Turn_Off_Charging: operation=RoutineServices_Turn_Off_HV_Turn_Off_Charging.Start
            OpServerCallDcm_MainFunction_Stop_RoutineServices_Turn_Off_HV_Turn_Off_Charging: operation=RoutineServices_Turn_Off_HV_Turn_Off_Charging.Stop
            OpServerCallDcm_MainFunction_Start_RoutineServices_Erase_Memory: operation=RoutineServices_Erase_Memory.Start
            OpServerCallDcm_MainFunction_Start_RoutineServices_CheckProgrammingDependencies: operation=RoutineServices_CheckProgrammingDependencies.Start
            OpServerCallDcm_MainFunction_ReadData_DataServices_DevelopmentData_Country_code: operation=DataServices_DevelopmentData_Country_code.ReadData
            OpServerCallDcm_MainFunction_ConditionCheckRead_DataServices_DevelopmentData_Country_code: operation=DataServices_DevelopmentData_Country_code.ConditionCheckRead
            OpServerCallDcm_MainFunction_ReadData_DataServices_DevelopmentData_Supplier_code: operation=DataServices_DevelopmentData_Supplier_code.ReadData
            OpServerCallDcm_MainFunction_ConditionCheckRead_DataServices_DevelopmentData_Supplier_code: operation=DataServices_DevelopmentData_Supplier_code.ConditionCheckRead
            OpServerCallDcm_MainFunction_ReadData_DataServices_DevelopmentData_Supplier_family_code: operation=DataServices_DevelopmentData_Supplier_family_code.ReadData
            OpServerCallDcm_MainFunction_ConditionCheckRead_DataServices_DevelopmentData_Supplier_family_code: operation=DataServices_DevelopmentData_Supplier_family_code.ConditionCheckRead
            OpServerCallDcm_MainFunction_ReadData_DataServices_EcuIdentification_Specific_Vehicle_Code_WMI: operation=DataServices_EcuIdentification_Specific_Vehicle_Code_WMI.ReadData
            OpServerCallDcm_MainFunction_ConditionCheckRead_DataServices_EcuIdentification_Specific_Vehicle_Code_WMI: operation=DataServices_EcuIdentification_Specific_Vehicle_Code_WMI.ConditionCheckRead
            OpServerCallDcm_MainFunction_WriteData_DataServices_EcuIdentification_Specific_Vehicle_Code_WMI: operation=DataServices_EcuIdentification_Specific_Vehicle_Code_WMI.WriteData
            OpServerCallDcm_MainFunction_ReadData_DataServices_EcuIdentification_Detail_Code: operation=DataServices_EcuIdentification_Detail_Code.ReadData
            OpServerCallDcm_MainFunction_ConditionCheckRead_DataServices_EcuIdentification_Detail_Code: operation=DataServices_EcuIdentification_Detail_Code.ConditionCheckRead
            OpServerCallDcm_MainFunction_WriteData_DataServices_EcuIdentification_Detail_Code: operation=DataServices_EcuIdentification_Detail_Code.WriteData
            OpServerCallDcm_MainFunction_ReadData_DataServices_EcuIdentification_Execution_Package: operation=DataServices_EcuIdentification_Execution_Package.ReadData
            OpServerCallDcm_MainFunction_ConditionCheckRead_DataServices_EcuIdentification_Execution_Package: operation=DataServices_EcuIdentification_Execution_Package.ConditionCheckRead
            OpServerCallDcm_MainFunction_WriteData_DataServices_EcuIdentification_Execution_Package: operation=DataServices_EcuIdentification_Execution_Package.WriteData
            OpServerCallDcm_MainFunction_ReadData_DataServices_EcuIdentification_Subgroup: operation=DataServices_EcuIdentification_Subgroup.ReadData
            OpServerCallDcm_MainFunction_ConditionCheckRead_DataServices_EcuIdentification_Subgroup: operation=DataServices_EcuIdentification_Subgroup.ConditionCheckRead
            OpServerCallDcm_MainFunction_WriteData_DataServices_EcuIdentification_Subgroup: operation=DataServices_EcuIdentification_Subgroup.WriteData
            OpServerCallDcm_MainFunction_ReadData_DataServices_EcuIdentification_Group: operation=DataServices_EcuIdentification_Group.ReadData
            OpServerCallDcm_MainFunction_ConditionCheckRead_DataServices_EcuIdentification_Group: operation=DataServices_EcuIdentification_Group.ConditionCheckRead
            OpServerCallDcm_MainFunction_WriteData_DataServices_EcuIdentification_Group: operation=DataServices_EcuIdentification_Group.WriteData
            OpServerCallDcm_MainFunction_ReadData_DataServices_SerialNumber_ECU_Name: operation=DataServices_SerialNumber_ECU_Name.ReadData
            OpServerCallDcm_MainFunction_ConditionCheckRead_DataServices_SerialNumber_ECU_Name: operation=DataServices_SerialNumber_ECU_Name.ConditionCheckRead
            OpServerCallDcm_MainFunction_ReadData_DataServices_SerialNumber_ECU_index_number: operation=DataServices_SerialNumber_ECU_index_number.ReadData
            OpServerCallDcm_MainFunction_ConditionCheckRead_DataServices_SerialNumber_ECU_index_number: operation=DataServices_SerialNumber_ECU_index_number.ConditionCheckRead
            OpServerCallDcm_MainFunction_ReadData_DataServices_SerialNumber_ECU_production_date_in_DD_MM_YY_format: operation=DataServices_SerialNumber_ECU_production_date_in_DD_MM_YY_format.ReadData
            OpServerCallDcm_MainFunction_ConditionCheckRead_DataServices_SerialNumber_ECU_production_date_in_DD_MM_YY_format: operation=DataServices_SerialNumber_ECU_production_date_in_DD_MM_YY_format.ConditionCheckRead
            OpServerCallDcm_MainFunction_ReadData_DataServices_SerialNumber_Supplier_name: operation=DataServices_SerialNumber_Supplier_name.ReadData
            OpServerCallDcm_MainFunction_ConditionCheckRead_DataServices_SerialNumber_Supplier_name: operation=DataServices_SerialNumber_Supplier_name.ConditionCheckRead
            OpServerCallDcm_MainFunction_ReadData_DataServices_AC_charging_parameter_VCU_OBC_ChargeCurrentCommand: operation=DataServices_AC_charging_parameter_VCU_OBC_ChargeCurrentCommand.ReadData
            OpServerCallDcm_MainFunction_ConditionCheckRead_DataServices_AC_charging_parameter_VCU_OBC_ChargeCurrentCommand: operation=DataServices_AC_charging_parameter_VCU_OBC_ChargeCurrentCommand.ConditionCheckRead
            OpServerCallDcm_MainFunction_ReadData_DataServices_AC_charging_parameter_POD_OBC_InputACVoltage: operation=DataServices_AC_charging_parameter_POD_OBC_InputACVoltage.ReadData
            OpServerCallDcm_MainFunction_ConditionCheckRead_DataServices_AC_charging_parameter_POD_OBC_InputACVoltage: operation=DataServices_AC_charging_parameter_POD_OBC_InputACVoltage.ConditionCheckRead
            OpServerCallDcm_MainFunction_ReadData_DataServices_AC_charging_parameter_POD_OBC_OutputDCChargeVoltage: operation=DataServices_AC_charging_parameter_POD_OBC_OutputDCChargeVoltage.ReadData
            OpServerCallDcm_MainFunction_ConditionCheckRead_DataServices_AC_charging_parameter_POD_OBC_OutputDCChargeVoltage: operation=DataServices_AC_charging_parameter_POD_OBC_OutputDCChargeVoltage.ConditionCheckRead
            OpServerCallDcm_MainFunction_ReadData_DataServices_AC_charging_parameter_POD_OBC_OutputDCChargeCurrent: operation=DataServices_AC_charging_parameter_POD_OBC_OutputDCChargeCurrent.ReadData
            OpServerCallDcm_MainFunction_ConditionCheckRead_DataServices_AC_charging_parameter_POD_OBC_OutputDCChargeCurrent: operation=DataServices_AC_charging_parameter_POD_OBC_OutputDCChargeCurrent.ConditionCheckRead
            OpServerCallDcm_MainFunction_WriteData_DataServices_Write_Level3_OEM_Key_OEM_Key_Value: operation=DataServices_Write_Level3_OEM_Key_OEM_Key_Value.WriteData
            OpServerCallDcm_MainFunction_WriteData_DataServices_Write_Level3_OEM_Key_CRC: operation=DataServices_Write_Level3_OEM_Key_CRC.WriteData
            OpServerCallDcm_MainFunction_ReadData_DataServices_Read_Vehicle_Security_related_events_Software_configuration_inte_Eve_94f062f2: operation=DataServices_Read_Vehicle_Security_related_events_Software_configuration_inte_Event_occurance_time_Year_1.ReadData
            OpServerCallDcm_MainFunction_ConditionCheckRead_DataServices_Read_Vehicle_Security_related_events_Software_configuratio_9d1010c9: operation=DataServices_Read_Vehicle_Security_related_events_Software_configuration_inte_Event_occurance_time_Year_1.ConditionCheckRead
            OpServerCallDcm_MainFunction_ReadData_DataServices_Read_Vehicle_Security_related_events_Software_configuration_inte_Eve_14342682: operation=DataServices_Read_Vehicle_Security_related_events_Software_configuration_inte_Event_occurance_time_Day_1.ReadData
            OpServerCallDcm_MainFunction_ConditionCheckRead_DataServices_Read_Vehicle_Security_related_events_Software_configuratio_420a368e: operation=DataServices_Read_Vehicle_Security_related_events_Software_configuration_inte_Event_occurance_time_Day_1.ConditionCheckRead
            OpServerCallDcm_MainFunction_ReadData_DataServices_Read_Vehicle_Security_related_events_Software_configuration_inte_Sof_71c08bd7: operation=DataServices_Read_Vehicle_Security_related_events_Software_configuration_inte_Software_configuration_integrity_check_fa_B04CEA39.ReadData
            OpServerCallDcm_MainFunction_ConditionCheckRead_DataServices_Read_Vehicle_Security_related_events_Software_configuratio_685b51a3: operation=DataServices_Read_Vehicle_Security_related_events_Software_configuration_inte_Software_configuration_integrity_check_fa_B04CEA39.ConditionCheckRead
            OpServerCallDcm_MainFunction_ReadData_DataServices_Read_Vehicle_Security_related_events_Software_configuration_inte_Eve_8d3d7738: operation=DataServices_Read_Vehicle_Security_related_events_Software_configuration_inte_Event_occurance_time_Day_2.ReadData
            OpServerCallDcm_MainFunction_ConditionCheckRead_DataServices_Read_Vehicle_Security_related_events_Software_configuratio_db036734: operation=DataServices_Read_Vehicle_Security_related_events_Software_configuration_inte_Event_occurance_time_Day_2.ConditionCheckRead
            OpServerCallDcm_MainFunction_ReadData_DataServices_Read_Vehicle_Security_related_events_Software_configuration_inte_Eve_fa3a47ae: operation=DataServices_Read_Vehicle_Security_related_events_Software_configuration_inte_Event_occurance_time_Day_3.ReadData
            OpServerCallDcm_MainFunction_ConditionCheckRead_DataServices_Read_Vehicle_Security_related_events_Software_configuratio_ac0457a2: operation=DataServices_Read_Vehicle_Security_related_events_Software_configuration_inte_Event_occurance_time_Day_3.ConditionCheckRead
            OpServerCallDcm_MainFunction_ReadData_DataServices_Read_Vehicle_Security_related_events_Software_configuration_inte_Eve_645ed20d: operation=DataServices_Read_Vehicle_Security_related_events_Software_configuration_inte_Event_occurance_time_Day_4.ReadData
            OpServerCallDcm_MainFunction_ConditionCheckRead_DataServices_Read_Vehicle_Security_related_events_Software_configuratio_3260c201: operation=DataServices_Read_Vehicle_Security_related_events_Software_configuration_inte_Event_occurance_time_Day_4.ConditionCheckRead
            OpServerCallDcm_MainFunction_ReadData_DataServices_Read_Vehicle_Security_related_events_Software_configuration_inte_Eve_1359e29b: operation=DataServices_Read_Vehicle_Security_related_events_Software_configuration_inte_Event_occurance_time_Day_5.ReadData
            OpServerCallDcm_MainFunction_ConditionCheckRead_DataServices_Read_Vehicle_Security_related_events_Software_configuratio_4567f297: operation=DataServices_Read_Vehicle_Security_related_events_Software_configuration_inte_Event_occurance_time_Day_5.ConditionCheckRead
            OpServerCallDcm_MainFunction_ReadData_DataServices_Read_Vehicle_Security_related_events_Software_configuration_inte_Sof_c638ff36: operation=DataServices_Read_Vehicle_Security_related_events_Software_configuration_inte_Software_configuration_integrity_check_5.ReadData
            OpServerCallDcm_MainFunction_ConditionCheckRead_DataServices_Read_Vehicle_Security_related_events_Software_configuratio_35d93abc: operation=DataServices_Read_Vehicle_Security_related_events_Software_configuration_inte_Software_configuration_integrity_check_5.ConditionCheckRead
            OpServerCallDcm_MainFunction_ReadData_DataServices_Read_Vehicle_Security_related_events_Software_configuration_inte_Eve_06993bd5: operation=DataServices_Read_Vehicle_Security_related_events_Software_configuration_inte_Event_occurance_time_Month_2.ReadData
            OpServerCallDcm_MainFunction_ConditionCheckRead_DataServices_Read_Vehicle_Security_related_events_Software_configuratio_b79b3283: operation=DataServices_Read_Vehicle_Security_related_events_Software_configuration_inte_Event_occurance_time_Month_2.ConditionCheckRead
            OpServerCallDcm_MainFunction_ReadData_DataServices_Read_Vehicle_Security_related_events_Software_configuration_inte_Eve_9f906a6f: operation=DataServices_Read_Vehicle_Security_related_events_Software_configuration_inte_Event_occurance_time_Month_1.ReadData
            OpServerCallDcm_MainFunction_ConditionCheckRead_DataServices_Read_Vehicle_Security_related_events_Software_configuratio_2e926339: operation=DataServices_Read_Vehicle_Security_related_events_Software_configuration_inte_Event_occurance_time_Month_1.ConditionCheckRead
            OpServerCallDcm_MainFunction_ReadData_DataServices_Read_Vehicle_Security_related_events_Software_configuration_inte_Eve_effa9ee0: operation=DataServices_Read_Vehicle_Security_related_events_Software_configuration_inte_Event_occurance_time_Month_4.ReadData
            OpServerCallDcm_MainFunction_ConditionCheckRead_DataServices_Read_Vehicle_Security_related_events_Software_configuratio_5ef897b6: operation=DataServices_Read_Vehicle_Security_related_events_Software_configuration_inte_Event_occurance_time_Month_4.ConditionCheckRead
            OpServerCallDcm_MainFunction_ReadData_DataServices_Read_Vehicle_Security_related_events_Software_configuration_inte_Sof_2f5b5a03: operation=DataServices_Read_Vehicle_Security_related_events_Software_configuration_inte_Software_configuration_integrity_check_3.ReadData
            OpServerCallDcm_MainFunction_ConditionCheckRead_DataServices_Read_Vehicle_Security_related_events_Software_configuratio_dcba9f89: operation=DataServices_Read_Vehicle_Security_related_events_Software_configuration_inte_Software_configuration_integrity_check_3.ConditionCheckRead
            OpServerCallDcm_MainFunction_ReadData_DataServices_Read_Vehicle_Security_related_events_Software_configuration_inte_Sof_b13fcfa0: operation=DataServices_Read_Vehicle_Security_related_events_Software_configuration_inte_Software_configuration_integrity_check_4.ReadData
            OpServerCallDcm_MainFunction_ConditionCheckRead_DataServices_Read_Vehicle_Security_related_events_Software_configuratio_42de0a2a: operation=DataServices_Read_Vehicle_Security_related_events_Software_configuration_inte_Software_configuration_integrity_check_4.ConditionCheckRead
            OpServerCallDcm_MainFunction_ReadData_DataServices_Read_Vehicle_Security_related_events_Software_configuration_inte_Eve_719e0b43: operation=DataServices_Read_Vehicle_Security_related_events_Software_configuration_inte_Event_occurance_time_Month_3.ReadData
            OpServerCallDcm_MainFunction_ConditionCheckRead_DataServices_Read_Vehicle_Security_related_events_Software_configuratio_c09c0215: operation=DataServices_Read_Vehicle_Security_related_events_Software_configuration_inte_Event_occurance_time_Month_3.ConditionCheckRead
            OpServerCallDcm_MainFunction_ReadData_DataServices_Read_Vehicle_Security_related_events_Software_configuration_inte_Sof_c1553b2f: operation=DataServices_Read_Vehicle_Security_related_events_Software_configuration_inte_Software_configuration_integrity_check_1.ReadData
            OpServerCallDcm_MainFunction_ConditionCheckRead_DataServices_Read_Vehicle_Security_related_events_Software_configuratio_32b4fea5: operation=DataServices_Read_Vehicle_Security_related_events_Software_configuration_inte_Software_configuration_integrity_check_1.ConditionCheckRead
            OpServerCallDcm_MainFunction_ReadData_DataServices_Read_Vehicle_Security_related_events_Software_configuration_inte_Eve_98fdae76: operation=DataServices_Read_Vehicle_Security_related_events_Software_configuration_inte_Event_occurance_time_Month_5.ReadData
            OpServerCallDcm_MainFunction_ConditionCheckRead_DataServices_Read_Vehicle_Security_related_events_Software_configuratio_29ffa720: operation=DataServices_Read_Vehicle_Security_related_events_Software_configuration_inte_Event_occurance_time_Month_5.ConditionCheckRead
            OpServerCallDcm_MainFunction_ReadData_DataServices_Read_Vehicle_Security_related_events_Software_configuration_inte_Sof_585c6a95: operation=DataServices_Read_Vehicle_Security_related_events_Software_configuration_inte_Software_configuration_integrity_check_2.ReadData
            OpServerCallDcm_MainFunction_ConditionCheckRead_DataServices_Read_Vehicle_Security_related_events_Software_configuratio_abbdaf1f: operation=DataServices_Read_Vehicle_Security_related_events_Software_configuration_inte_Software_configuration_integrity_check_2.ConditionCheckRead
            OpServerCallDcm_MainFunction_ReadData_DataServices_Read_Vehicle_Security_related_events_Software_configuration_inte_Eve_e49a967d: operation=DataServices_Read_Vehicle_Security_related_events_Software_configuration_inte_Event_occurance_time_Year_4.ReadData
            OpServerCallDcm_MainFunction_ConditionCheckRead_DataServices_Read_Vehicle_Security_related_events_Software_configuratio_ed7ae446: operation=DataServices_Read_Vehicle_Security_related_events_Software_configuration_inte_Event_occurance_time_Year_4.ConditionCheckRead
            OpServerCallDcm_MainFunction_ReadData_DataServices_Read_Vehicle_Security_related_events_Software_configuration_inte_Eve_939da6eb: operation=DataServices_Read_Vehicle_Security_related_events_Software_configuration_inte_Event_occurance_time_Year_5.ReadData
            OpServerCallDcm_MainFunction_ConditionCheckRead_DataServices_Read_Vehicle_Security_related_events_Software_configuratio_9a7dd4d0: operation=DataServices_Read_Vehicle_Security_related_events_Software_configuration_inte_Event_occurance_time_Year_5.ConditionCheckRead
            OpServerCallDcm_MainFunction_ReadData_DataServices_Read_Vehicle_Security_related_events_Software_configuration_inte_Eve_0df93348: operation=DataServices_Read_Vehicle_Security_related_events_Software_configuration_inte_Event_occurance_time_Year_2.ReadData
            OpServerCallDcm_MainFunction_ConditionCheckRead_DataServices_Read_Vehicle_Security_related_events_Software_configuratio_04194173: operation=DataServices_Read_Vehicle_Security_related_events_Software_configuration_inte_Event_occurance_time_Year_2.ConditionCheckRead
            OpServerCallDcm_MainFunction_ReadData_DataServices_Read_Vehicle_Security_related_events_Software_configuration_inte_Eve_7afe03de: operation=DataServices_Read_Vehicle_Security_related_events_Software_configuration_inte_Event_occurance_time_Year_3.ReadData
            OpServerCallDcm_MainFunction_ConditionCheckRead_DataServices_Read_Vehicle_Security_related_events_Software_configuratio_731e71e5: operation=DataServices_Read_Vehicle_Security_related_events_Software_configuration_inte_Event_occurance_time_Year_3.ConditionCheckRead
            OpServerCallDcm_MainFunction_ReadData_DataServices_BS_base_information4_SOF_V2: operation=DataServices_BS_base_information4_SOF_V2.ReadData
            OpServerCallDcm_MainFunction_ConditionCheckRead_DataServices_BS_base_information4_SOF_V2: operation=DataServices_BS_base_information4_SOF_V2.ConditionCheckRead
            OpServerCallDcm_MainFunction_ReadData_DataServices_BS_base_information4_VCU_BS_Hcurrent: operation=DataServices_BS_base_information4_VCU_BS_Hcurrent.ReadData
            OpServerCallDcm_MainFunction_ConditionCheckRead_DataServices_BS_base_information4_VCU_BS_Hcurrent: operation=DataServices_BS_base_information4_VCU_BS_Hcurrent.ConditionCheckRead
            OpServerCallDcm_MainFunction_ReadData_DataServices_BS_base_information4_SOF_V1: operation=DataServices_BS_base_information4_SOF_V1.ReadData
            OpServerCallDcm_MainFunction_ConditionCheckRead_DataServices_BS_base_information4_SOF_V1: operation=DataServices_BS_base_information4_SOF_V1.ConditionCheckRead
            OpServerCallDcm_MainFunction_ReadData_DataServices_BS_base_information4_SOH: operation=DataServices_BS_base_information4_SOH.ReadData
            OpServerCallDcm_MainFunction_ConditionCheckRead_DataServices_BS_base_information4_SOH: operation=DataServices_BS_base_information4_SOH.ConditionCheckRead
            OpServerCallDcm_MainFunction_ReadData_DataServices_BS_base_information4_BS_SOC: operation=DataServices_BS_base_information4_BS_SOC.ReadData
            OpServerCallDcm_MainFunction_ConditionCheckRead_DataServices_BS_base_information4_BS_SOC: operation=DataServices_BS_base_information4_BS_SOC.ConditionCheckRead
            OpServerCallDcm_MainFunction_ReadData_DataServices_BS_base_information4_T_BATT: operation=DataServices_BS_base_information4_T_BATT.ReadData
            OpServerCallDcm_MainFunction_ConditionCheckRead_DataServices_BS_base_information4_T_BATT: operation=DataServices_BS_base_information4_T_BATT.ConditionCheckRead
            OpServerCallDcm_MainFunction_ReadData_DataServices_Read_Level4_OEM_Key_written_status_Read_Level4_OEM_Key_rewrite_counter: operation=DataServices_Read_Level4_OEM_Key_written_status_Read_Level4_OEM_Key_rewrite_counter.ReadData
            OpServerCallDcm_MainFunction_ConditionCheckRead_DataServices_Read_Level4_OEM_Key_written_status_Read_Level4_OEM_Key_rew_d34410c6: operation=DataServices_Read_Level4_OEM_Key_written_status_Read_Level4_OEM_Key_rewrite_counter.ConditionCheckRead
            OpServerCallDcm_MainFunction_ReadData_DataServices_Read_active_diagnostic_session_Active_diagnostic_session: operation=DataServices_Read_active_diagnostic_session_Active_diagnostic_session.ReadData
            OpServerCallDcm_MainFunction_ConditionCheckRead_DataServices_Read_active_diagnostic_session_Active_diagnostic_session: operation=DataServices_Read_active_diagnostic_session_Active_diagnostic_session.ConditionCheckRead
            OpServerCallDcm_MainFunction_ReadData_DataServices_Total_Odometer_VCU_Total_Odometer_VCU: operation=DataServices_Total_Odometer_VCU_Total_Odometer_VCU.ReadData
            OpServerCallDcm_MainFunction_ConditionCheckRead_DataServices_Total_Odometer_VCU_Total_Odometer_VCU: operation=DataServices_Total_Odometer_VCU_Total_Odometer_VCU.ConditionCheckRead
            OpServerCallDcm_MainFunction_WriteData_DataServices_Total_Odometer_VCU_Total_Odometer_VCU: operation=DataServices_Total_Odometer_VCU_Total_Odometer_VCU.WriteData
            OpServerCallDcm_MainFunction_ReadData_DataServices_VCU_HVStatus_VCU_HVStatus: operation=DataServices_VCU_HVStatus_VCU_HVStatus.ReadData
            OpServerCallDcm_MainFunction_ConditionCheckRead_DataServices_VCU_HVStatus_VCU_HVStatus: operation=DataServices_VCU_HVStatus_VCU_HVStatus.ConditionCheckRead
            OpServerCallDcm_MainFunction_ReadData_DataServices_Vehicle_speed_Vehicle_speed: operation=DataServices_Vehicle_speed_Vehicle_speed.ReadData
            OpServerCallDcm_MainFunction_ConditionCheckRead_DataServices_Vehicle_speed_Vehicle_speed: operation=DataServices_Vehicle_speed_Vehicle_speed.ConditionCheckRead
            OpServerCallDcm_MainFunction_ReadData_DataServices_Read_ECU_manufacturing_date_ECU_Manufacturing_Date_Day: operation=DataServices_Read_ECU_manufacturing_date_ECU_Manufacturing_Date_Day.ReadData
            OpServerCallDcm_MainFunction_ConditionCheckRead_DataServices_Read_ECU_manufacturing_date_ECU_Manufacturing_Date_Day: operation=DataServices_Read_ECU_manufacturing_date_ECU_Manufacturing_Date_Day.ConditionCheckRead
            OpServerCallDcm_MainFunction_ReadData_DataServices_Read_ECU_manufacturing_date_ECU_Manufacturing_Date_Month: operation=DataServices_Read_ECU_manufacturing_date_ECU_Manufacturing_Date_Month.ReadData
            OpServerCallDcm_MainFunction_ConditionCheckRead_DataServices_Read_ECU_manufacturing_date_ECU_Manufacturing_Date_Month: operation=DataServices_Read_ECU_manufacturing_date_ECU_Manufacturing_Date_Month.ConditionCheckRead
            OpServerCallDcm_MainFunction_ReadData_DataServices_Read_ECU_manufacturing_date_ECU_Manufacturing_Date_Year: operation=DataServices_Read_ECU_manufacturing_date_ECU_Manufacturing_Date_Year.ReadData
            OpServerCallDcm_MainFunction_ConditionCheckRead_DataServices_Read_ECU_manufacturing_date_ECU_Manufacturing_Date_Year: operation=DataServices_Read_ECU_manufacturing_date_ECU_Manufacturing_Date_Year.ConditionCheckRead
            OpServerCallDcm_MainFunction_ReadData_DataServices_HV_Status_and_Charging_Status_HV_status_and_charging_status: operation=DataServices_HV_Status_and_Charging_Status_HV_status_and_charging_status.ReadData
            OpServerCallDcm_MainFunction_ConditionCheckRead_DataServices_HV_Status_and_Charging_Status_HV_status_and_charging_status: operation=DataServices_HV_Status_and_Charging_Status_HV_status_and_charging_status.ConditionCheckRead
            OpServerCallDcm_MainFunction_ReadData_DataServices_SOC_SOC: operation=DataServices_SOC_SOC.ReadData
            OpServerCallDcm_MainFunction_ConditionCheckRead_DataServices_SOC_SOC: operation=DataServices_SOC_SOC.ConditionCheckRead
            OpServerCallDcm_MainFunction_ReadData_DataServices_Supplier_ECU_hardware_part_number_Major_release: operation=DataServices_Supplier_ECU_hardware_part_number_Major_release.ReadData
            OpServerCallDcm_MainFunction_ConditionCheckRead_DataServices_Supplier_ECU_hardware_part_number_Major_release: operation=DataServices_Supplier_ECU_hardware_part_number_Major_release.ConditionCheckRead
            OpServerCallDcm_MainFunction_ReadData_DataServices_Supplier_ECU_hardware_part_number_Changes_in_electronic_components_level: operation=DataServices_Supplier_ECU_hardware_part_number_Changes_in_electronic_components_level.ReadData
            OpServerCallDcm_MainFunction_ConditionCheckRead_DataServices_Supplier_ECU_hardware_part_number_Changes_in_electronic_co_aad44563: operation=DataServices_Supplier_ECU_hardware_part_number_Changes_in_electronic_components_level.ConditionCheckRead
            OpServerCallDcm_MainFunction_WriteData_DataServices_Write_Level4_OEM_Key_OEM_Key_Value: operation=DataServices_Write_Level4_OEM_Key_OEM_Key_Value.WriteData
            OpServerCallDcm_MainFunction_WriteData_DataServices_Write_Level4_OEM_Key_CRC: operation=DataServices_Write_Level4_OEM_Key_CRC.WriteData
            OpServerCallDcm_MainFunction_ReadData_DataServices_VCU_AccPealparameter_VCU_AccelerationPedal: operation=DataServices_VCU_AccPealparameter_VCU_AccelerationPedal.ReadData
            OpServerCallDcm_MainFunction_ConditionCheckRead_DataServices_VCU_AccPealparameter_VCU_AccelerationPedal: operation=DataServices_VCU_AccPealparameter_VCU_AccelerationPedal.ConditionCheckRead
            OpServerCallDcm_MainFunction_ReadData_DataServices_VCU_AccPealparameter_Accelerator_pedal_sensor_2_voltage: operation=DataServices_VCU_AccPealparameter_Accelerator_pedal_sensor_2_voltage.ReadData
            OpServerCallDcm_MainFunction_ConditionCheckRead_DataServices_VCU_AccPealparameter_Accelerator_pedal_sensor_2_voltage: operation=DataServices_VCU_AccPealparameter_Accelerator_pedal_sensor_2_voltage.ConditionCheckRead
            OpServerCallDcm_MainFunction_ReadData_DataServices_VCU_AccPealparameter_Accelerator_pedal_sensor_1_voltage: operation=DataServices_VCU_AccPealparameter_Accelerator_pedal_sensor_1_voltage.ReadData
            OpServerCallDcm_MainFunction_ConditionCheckRead_DataServices_VCU_AccPealparameter_Accelerator_pedal_sensor_1_voltage: operation=DataServices_VCU_AccPealparameter_Accelerator_pedal_sensor_1_voltage.ConditionCheckRead
            OpServerCallDcm_MainFunction_ReadData_DataServices_VCU_AccPealparameter_VCU_VehicleSpeed: operation=DataServices_VCU_AccPealparameter_VCU_VehicleSpeed.ReadData
            OpServerCallDcm_MainFunction_ConditionCheckRead_DataServices_VCU_AccPealparameter_VCU_VehicleSpeed: operation=DataServices_VCU_AccPealparameter_VCU_VehicleSpeed.ConditionCheckRead
            OpServerCallDcm_MainFunction_ReadData_DataServices_HV_part_work_mode_HV_part_work_mode1: operation=DataServices_HV_part_work_mode_HV_part_work_mode1.ReadData
            OpServerCallDcm_MainFunction_ConditionCheckRead_DataServices_HV_part_work_mode_HV_part_work_mode1: operation=DataServices_HV_part_work_mode_HV_part_work_mode1.ConditionCheckRead
            OpServerCallDcm_MainFunction_ReadData_DataServices_HV_part_work_mode_HV_part_work_mode2: operation=DataServices_HV_part_work_mode_HV_part_work_mode2.ReadData
            OpServerCallDcm_MainFunction_ConditionCheckRead_DataServices_HV_part_work_mode_HV_part_work_mode2: operation=DataServices_HV_part_work_mode_HV_part_work_mode2.ConditionCheckRead
            OpServerCallDcm_MainFunction_ReadData_DataServices_Bootloader_version_number_Major_release: operation=DataServices_Bootloader_version_number_Major_release.ReadData
            OpServerCallDcm_MainFunction_ConditionCheckRead_DataServices_Bootloader_version_number_Major_release: operation=DataServices_Bootloader_version_number_Major_release.ConditionCheckRead
            OpServerCallDcm_MainFunction_ReadData_DataServices_Bootloader_version_number_Minor_release: operation=DataServices_Bootloader_version_number_Minor_release.ReadData
            OpServerCallDcm_MainFunction_ConditionCheckRead_DataServices_Bootloader_version_number_Minor_release: operation=DataServices_Bootloader_version_number_Minor_release.ConditionCheckRead
            OpServerCallDcm_MainFunction_ReadData_DataServices_Bootloader_version_number_No_functional_content_change: operation=DataServices_Bootloader_version_number_No_functional_content_change.ReadData
            OpServerCallDcm_MainFunction_ConditionCheckRead_DataServices_Bootloader_version_number_No_functional_content_change: operation=DataServices_Bootloader_version_number_No_functional_content_change.ConditionCheckRead
            OpServerCallDcm_MainFunction_ReadData_DataServices_Read_Level1_OEM_Key_written_status_Read_Level1_OEM_Key_rewrite_counter: operation=DataServices_Read_Level1_OEM_Key_written_status_Read_Level1_OEM_Key_rewrite_counter.ReadData
            OpServerCallDcm_MainFunction_ConditionCheckRead_DataServices_Read_Level1_OEM_Key_written_status_Read_Level1_OEM_Key_rew_da0d7202: operation=DataServices_Read_Level1_OEM_Key_written_status_Read_Level1_OEM_Key_rewrite_counter.ConditionCheckRead
            OpServerCallDcm_MainFunction_ReadData_DataServices_Coding_for_CDS_fingerprint_codingDate_byte_3_DD: operation=DataServices_Coding_for_CDS_fingerprint_codingDate_byte_3_DD.ReadData
            OpServerCallDcm_MainFunction_ConditionCheckRead_DataServices_Coding_for_CDS_fingerprint_codingDate_byte_3_DD: operation=DataServices_Coding_for_CDS_fingerprint_codingDate_byte_3_DD.ConditionCheckRead
            OpServerCallDcm_MainFunction_WriteData_DataServices_Coding_for_CDS_fingerprint_codingDate_byte_3_DD: operation=DataServices_Coding_for_CDS_fingerprint_codingDate_byte_3_DD.WriteData
            OpServerCallDcm_MainFunction_ReadData_DataServices_Coding_for_CDS_fingerprint_codingDate_byte_2_MM: operation=DataServices_Coding_for_CDS_fingerprint_codingDate_byte_2_MM.ReadData
            OpServerCallDcm_MainFunction_ConditionCheckRead_DataServices_Coding_for_CDS_fingerprint_codingDate_byte_2_MM: operation=DataServices_Coding_for_CDS_fingerprint_codingDate_byte_2_MM.ConditionCheckRead
            OpServerCallDcm_MainFunction_WriteData_DataServices_Coding_for_CDS_fingerprint_codingDate_byte_2_MM: operation=DataServices_Coding_for_CDS_fingerprint_codingDate_byte_2_MM.WriteData
            OpServerCallDcm_MainFunction_ReadData_DataServices_Coding_for_CDS_fingerprint_codingDate_byte_1_YY: operation=DataServices_Coding_for_CDS_fingerprint_codingDate_byte_1_YY.ReadData
            OpServerCallDcm_MainFunction_ConditionCheckRead_DataServices_Coding_for_CDS_fingerprint_codingDate_byte_1_YY: operation=DataServices_Coding_for_CDS_fingerprint_codingDate_byte_1_YY.ConditionCheckRead
            OpServerCallDcm_MainFunction_WriteData_DataServices_Coding_for_CDS_fingerprint_codingDate_byte_1_YY: operation=DataServices_Coding_for_CDS_fingerprint_codingDate_byte_1_YY.WriteData
            OpServerCallDcm_MainFunction_ReadData_DataServices_Coding_for_CDS_fingerprint_repairShopCodeorTesterSerialNumber_byte_1_27_MSB: operation=DataServices_Coding_for_CDS_fingerprint_repairShopCodeorTesterSerialNumber_byte_1_27_MSB.ReadData
            OpServerCallDcm_MainFunction_ConditionCheckRead_DataServices_Coding_for_CDS_fingerprint_repairShopCodeorTesterSerialNum_0da5a306: operation=DataServices_Coding_for_CDS_fingerprint_repairShopCodeorTesterSerialNumber_byte_1_27_MSB.ConditionCheckRead
            OpServerCallDcm_MainFunction_WriteData_DataServices_Coding_for_CDS_fingerprint_repairShopCodeorTesterSerialNumber_byte_1_27_MSB: operation=DataServices_Coding_for_CDS_fingerprint_repairShopCodeorTesterSerialNumber_byte_1_27_MSB.WriteData
            OpServerCallDcm_MainFunction_ReadData_DataServices_VCU_control_main_relay_Mainrealy1: operation=DataServices_VCU_control_main_relay_Mainrealy1.ReadData
            OpServerCallDcm_MainFunction_ConditionCheckRead_DataServices_VCU_control_main_relay_Mainrealy1: operation=DataServices_VCU_control_main_relay_Mainrealy1.ConditionCheckRead
            OpServerCallDcm_MainFunction_ReadData_DataServices_VCU_control_main_relay_Mainrelay2: operation=DataServices_VCU_control_main_relay_Mainrelay2.ReadData
            OpServerCallDcm_MainFunction_ConditionCheckRead_DataServices_VCU_control_main_relay_Mainrelay2: operation=DataServices_VCU_control_main_relay_Mainrelay2.ConditionCheckRead
            OpServerCallDcm_MainFunction_ReadData_DataServices_VCU_control_S2_status_New_Bit_Field: operation=DataServices_VCU_control_S2_status_New_Bit_Field.ReadData
            OpServerCallDcm_MainFunction_ConditionCheckRead_DataServices_VCU_control_S2_status_New_Bit_Field: operation=DataServices_VCU_control_S2_status_New_Bit_Field.ConditionCheckRead
            OpServerCallDcm_MainFunction_ReadData_DataServices_Electronic_lock_state_Electronic_lock_state: operation=DataServices_Electronic_lock_state_Electronic_lock_state.ReadData
            OpServerCallDcm_MainFunction_ConditionCheckRead_DataServices_Electronic_lock_state_Electronic_lock_state: operation=DataServices_Electronic_lock_state_Electronic_lock_state.ConditionCheckRead
            OpServerCallDcm_MainFunction_ReadData_DataServices_DC_Charging_port_Temperature_POD_DCInletTempA: operation=DataServices_DC_Charging_port_Temperature_POD_DCInletTempA.ReadData
            OpServerCallDcm_MainFunction_ConditionCheckRead_DataServices_DC_Charging_port_Temperature_POD_DCInletTempA: operation=DataServices_DC_Charging_port_Temperature_POD_DCInletTempA.ConditionCheckRead
            OpServerCallDcm_MainFunction_ReadData_DataServices_DC_Charging_port_Temperature_POD_DCInletTempB: operation=DataServices_DC_Charging_port_Temperature_POD_DCInletTempB.ReadData
            OpServerCallDcm_MainFunction_ConditionCheckRead_DataServices_DC_Charging_port_Temperature_POD_DCInletTempB: operation=DataServices_DC_Charging_port_Temperature_POD_DCInletTempB.ConditionCheckRead
            OpServerCallDcm_MainFunction_ReadData_DataServices_Total_Odometer_Total_Odometer: operation=DataServices_Total_Odometer_Total_Odometer.ReadData
            OpServerCallDcm_MainFunction_ConditionCheckRead_DataServices_Total_Odometer_Total_Odometer: operation=DataServices_Total_Odometer_Total_Odometer.ConditionCheckRead
            OpServerCallDcm_MainFunction_ReadData_DataServices_VCU_HV_InterLock_PWM_pfrequency_VCU_HVIL: operation=DataServices_VCU_HV_InterLock_PWM_pfrequency_VCU_HVIL.ReadData
            OpServerCallDcm_MainFunction_ConditionCheckRead_DataServices_VCU_HV_InterLock_PWM_pfrequency_VCU_HVIL: operation=DataServices_VCU_HV_InterLock_PWM_pfrequency_VCU_HVIL.ConditionCheckRead
            OpServerCallDcm_MainFunction_ReadData_DataServices_PWT_vehicle_fault_PWT_ErrorLevel1: operation=DataServices_PWT_vehicle_fault_PWT_ErrorLevel1.ReadData
            OpServerCallDcm_MainFunction_ConditionCheckRead_DataServices_PWT_vehicle_fault_PWT_ErrorLevel1: operation=DataServices_PWT_vehicle_fault_PWT_ErrorLevel1.ConditionCheckRead
            OpServerCallDcm_MainFunction_ReadData_DataServices_PWT_vehicle_fault_PWT_ErrorLevel2: operation=DataServices_PWT_vehicle_fault_PWT_ErrorLevel2.ReadData
            OpServerCallDcm_MainFunction_ConditionCheckRead_DataServices_PWT_vehicle_fault_PWT_ErrorLevel2: operation=DataServices_PWT_vehicle_fault_PWT_ErrorLevel2.ConditionCheckRead
            OpServerCallDcm_MainFunction_ReadData_DataServices_PWT_vehicle_fault_PWT_ErrorLevel3: operation=DataServices_PWT_vehicle_fault_PWT_ErrorLevel3.ReadData
            OpServerCallDcm_MainFunction_ConditionCheckRead_DataServices_PWT_vehicle_fault_PWT_ErrorLevel3: operation=DataServices_PWT_vehicle_fault_PWT_ErrorLevel3.ConditionCheckRead
            OpServerCallDcm_MainFunction_ReadData_DataServices_VCU_PowerMaxAllowed_parameter1_VCU_DisChgPowerLimit: operation=DataServices_VCU_PowerMaxAllowed_parameter1_VCU_DisChgPowerLimit.ReadData
            OpServerCallDcm_MainFunction_ConditionCheckRead_DataServices_VCU_PowerMaxAllowed_parameter1_VCU_DisChgPowerLimit: operation=DataServices_VCU_PowerMaxAllowed_parameter1_VCU_DisChgPowerLimit.ConditionCheckRead
            OpServerCallDcm_MainFunction_ReadData_DataServices_VCU_PowerMaxAllowed_parameter1_VCU_TCUPowerAllowed: operation=DataServices_VCU_PowerMaxAllowed_parameter1_VCU_TCUPowerAllowed.ReadData
            OpServerCallDcm_MainFunction_ConditionCheckRead_DataServices_VCU_PowerMaxAllowed_parameter1_VCU_TCUPowerAllowed: operation=DataServices_VCU_PowerMaxAllowed_parameter1_VCU_TCUPowerAllowed.ConditionCheckRead
            OpServerCallDcm_MainFunction_ReadData_DataServices_VCU_PowerMaxAllowed_parameter1_VCU_DCDCPowerLimit: operation=DataServices_VCU_PowerMaxAllowed_parameter1_VCU_DCDCPowerLimit.ReadData
            OpServerCallDcm_MainFunction_ConditionCheckRead_DataServices_VCU_PowerMaxAllowed_parameter1_VCU_DCDCPowerLimit: operation=DataServices_VCU_PowerMaxAllowed_parameter1_VCU_DCDCPowerLimit.ConditionCheckRead
            OpServerCallDcm_MainFunction_ReadData_DataServices_VCU_PowerMaxAllowed_parameter1_MCUPowerLimit: operation=DataServices_VCU_PowerMaxAllowed_parameter1_MCUPowerLimit.ReadData
            OpServerCallDcm_MainFunction_ConditionCheckRead_DataServices_VCU_PowerMaxAllowed_parameter1_MCUPowerLimit: operation=DataServices_VCU_PowerMaxAllowed_parameter1_MCUPowerLimit.ConditionCheckRead
            OpServerCallDcm_MainFunction_ReadData_DataServices_VCU_PowerMaxAllowed_parameter2_BMSChgPowerLimit: operation=DataServices_VCU_PowerMaxAllowed_parameter2_BMSChgPowerLimit.ReadData
            OpServerCallDcm_MainFunction_ConditionCheckRead_DataServices_VCU_PowerMaxAllowed_parameter2_BMSChgPowerLimit: operation=DataServices_VCU_PowerMaxAllowed_parameter2_BMSChgPowerLimit.ConditionCheckRead
            OpServerCallDcm_MainFunction_ReadData_DataServices_VCU_PowerMaxAllowed_parameter2_MCUFeedbackPowerLimit: operation=DataServices_VCU_PowerMaxAllowed_parameter2_MCUFeedbackPowerLimit.ReadData
            OpServerCallDcm_MainFunction_ConditionCheckRead_DataServices_VCU_PowerMaxAllowed_parameter2_MCUFeedbackPowerLimit: operation=DataServices_VCU_PowerMaxAllowed_parameter2_MCUFeedbackPowerLimit.ConditionCheckRead
            OpServerCallDcm_MainFunction_ReadData_DataServices_VCU_PowerMaxAllowed_parameter2_BMSDisChgPowerLimit: operation=DataServices_VCU_PowerMaxAllowed_parameter2_BMSDisChgPowerLimit.ReadData
            OpServerCallDcm_MainFunction_ConditionCheckRead_DataServices_VCU_PowerMaxAllowed_parameter2_BMSDisChgPowerLimit: operation=DataServices_VCU_PowerMaxAllowed_parameter2_BMSDisChgPowerLimit.ConditionCheckRead
            OpServerCallDcm_MainFunction_ReadData_DataServices_VCU_PowerMaxAllowed_parameter3_ACSystemPower: operation=DataServices_VCU_PowerMaxAllowed_parameter3_ACSystemPower.ReadData
            OpServerCallDcm_MainFunction_ConditionCheckRead_DataServices_VCU_PowerMaxAllowed_parameter3_ACSystemPower: operation=DataServices_VCU_PowerMaxAllowed_parameter3_ACSystemPower.ConditionCheckRead
            OpServerCallDcm_MainFunction_ReadData_DataServices_VCU_PowerMaxAllowed_parameter3_V2LPower: operation=DataServices_VCU_PowerMaxAllowed_parameter3_V2LPower.ReadData
            OpServerCallDcm_MainFunction_ConditionCheckRead_DataServices_VCU_PowerMaxAllowed_parameter3_V2LPower: operation=DataServices_VCU_PowerMaxAllowed_parameter3_V2LPower.ConditionCheckRead
            OpServerCallDcm_MainFunction_ReadData_DataServices_VCU_PowerMaxAllowed_parameter3_PackPTCPower: operation=DataServices_VCU_PowerMaxAllowed_parameter3_PackPTCPower.ReadData
            OpServerCallDcm_MainFunction_ConditionCheckRead_DataServices_VCU_PowerMaxAllowed_parameter3_PackPTCPower: operation=DataServices_VCU_PowerMaxAllowed_parameter3_PackPTCPower.ConditionCheckRead
            OpServerCallDcm_MainFunction_ReadData_DataServices_VCU_PowerMaxAllowed_parameter3_MCUPower: operation=DataServices_VCU_PowerMaxAllowed_parameter3_MCUPower.ReadData
            OpServerCallDcm_MainFunction_ConditionCheckRead_DataServices_VCU_PowerMaxAllowed_parameter3_MCUPower: operation=DataServices_VCU_PowerMaxAllowed_parameter3_MCUPower.ConditionCheckRead
            OpServerCallDcm_MainFunction_ReadData_DataServices_VCU_PowerMaxAllowed_parameter3_DCDCPower: operation=DataServices_VCU_PowerMaxAllowed_parameter3_DCDCPower.ReadData
            OpServerCallDcm_MainFunction_ConditionCheckRead_DataServices_VCU_PowerMaxAllowed_parameter3_DCDCPower: operation=DataServices_VCU_PowerMaxAllowed_parameter3_DCDCPower.ConditionCheckRead
            OpServerCallDcm_MainFunction_ReadData_DataServices_Gear_Gear: operation=DataServices_Gear_Gear.ReadData
            OpServerCallDcm_MainFunction_ConditionCheckRead_DataServices_Gear_Gear: operation=DataServices_Gear_Gear.ConditionCheckRead
            OpServerCallDcm_MainFunction_ReadData_DataServices_Chargestatus_Chargestatus: operation=DataServices_Chargestatus_Chargestatus.ReadData
            OpServerCallDcm_MainFunction_ConditionCheckRead_DataServices_Chargestatus_Chargestatus: operation=DataServices_Chargestatus_Chargestatus.ConditionCheckRead
            OpServerCallDcm_MainFunction_ReadData_DataServices_Read_Level2_OEM_Key_written_status_Read_Level2_OEM_Key_rewrite_counter: operation=DataServices_Read_Level2_OEM_Key_written_status_Read_Level2_OEM_Key_rewrite_counter.ReadData
            OpServerCallDcm_MainFunction_ConditionCheckRead_DataServices_Read_Level2_OEM_Key_written_status_Read_Level2_OEM_Key_rew_6be55181: operation=DataServices_Read_Level2_OEM_Key_written_status_Read_Level2_OEM_Key_rewrite_counter.ConditionCheckRead
            OpServerCallDcm_MainFunction_ReadData_DataServices_Vehicle_State_Ignition_Switch_Signal: operation=DataServices_Vehicle_State_Ignition_Switch_Signal.ReadData
            OpServerCallDcm_MainFunction_ConditionCheckRead_DataServices_Vehicle_State_Ignition_Switch_Signal: operation=DataServices_Vehicle_State_Ignition_Switch_Signal.ConditionCheckRead
            OpServerCallDcm_MainFunction_ReadData_DataServices_Read_ECU_Part_Number_Specific_Vehicle_Code_WMI: operation=DataServices_Read_ECU_Part_Number_Specific_Vehicle_Code_WMI.ReadData
            OpServerCallDcm_MainFunction_ConditionCheckRead_DataServices_Read_ECU_Part_Number_Specific_Vehicle_Code_WMI: operation=DataServices_Read_ECU_Part_Number_Specific_Vehicle_Code_WMI.ConditionCheckRead
            OpServerCallDcm_MainFunction_ReadData_DataServices_Read_ECU_Part_Number_Detail_Code: operation=DataServices_Read_ECU_Part_Number_Detail_Code.ReadData
            OpServerCallDcm_MainFunction_ConditionCheckRead_DataServices_Read_ECU_Part_Number_Detail_Code: operation=DataServices_Read_ECU_Part_Number_Detail_Code.ConditionCheckRead
            OpServerCallDcm_MainFunction_ReadData_DataServices_Read_ECU_Part_Number_Execution_Package: operation=DataServices_Read_ECU_Part_Number_Execution_Package.ReadData
            OpServerCallDcm_MainFunction_ConditionCheckRead_DataServices_Read_ECU_Part_Number_Execution_Package: operation=DataServices_Read_ECU_Part_Number_Execution_Package.ConditionCheckRead
            OpServerCallDcm_MainFunction_ReadData_DataServices_Read_ECU_Part_Number_Subgroup: operation=DataServices_Read_ECU_Part_Number_Subgroup.ReadData
            OpServerCallDcm_MainFunction_ConditionCheckRead_DataServices_Read_ECU_Part_Number_Subgroup: operation=DataServices_Read_ECU_Part_Number_Subgroup.ConditionCheckRead
            OpServerCallDcm_MainFunction_ReadData_DataServices_Read_ECU_Part_Number_Group: operation=DataServices_Read_ECU_Part_Number_Group.ReadData
            OpServerCallDcm_MainFunction_ConditionCheckRead_DataServices_Read_ECU_Part_Number_Group: operation=DataServices_Read_ECU_Part_Number_Group.ConditionCheckRead
            OpServerCallDcm_MainFunction_WriteData_DataServices_Write_Level2_OEM_Key_OEM_Key_Value: operation=DataServices_Write_Level2_OEM_Key_OEM_Key_Value.WriteData
            OpServerCallDcm_MainFunction_WriteData_DataServices_Write_Level2_OEM_Key_CRC: operation=DataServices_Write_Level2_OEM_Key_CRC.WriteData
            OpServerCallDcm_MainFunction_ReadData_DataServices_BSW_version_number_Major_release: operation=DataServices_BSW_version_number_Major_release.ReadData
            OpServerCallDcm_MainFunction_ConditionCheckRead_DataServices_BSW_version_number_Major_release: operation=DataServices_BSW_version_number_Major_release.ConditionCheckRead
            OpServerCallDcm_MainFunction_ReadData_DataServices_BSW_version_number_Minor_release: operation=DataServices_BSW_version_number_Minor_release.ReadData
            OpServerCallDcm_MainFunction_ConditionCheckRead_DataServices_BSW_version_number_Minor_release: operation=DataServices_BSW_version_number_Minor_release.ConditionCheckRead
            OpServerCallDcm_MainFunction_ReadData_DataServices_BSW_version_number_No_functional_content_change: operation=DataServices_BSW_version_number_No_functional_content_change.ReadData
            OpServerCallDcm_MainFunction_ConditionCheckRead_DataServices_BSW_version_number_No_functional_content_change: operation=DataServices_BSW_version_number_No_functional_content_change.ConditionCheckRead
            OpServerCallDcm_MainFunction_ReadData_DataServices_Read_Vehicle_Security_related_events_Brute_Force_UDS_0x27_servic_Eve_2af1ff31: operation=DataServices_Read_Vehicle_Security_related_events_Brute_Force_UDS_0x27_servic_Event_occurance_time_Year_1.ReadData
            OpServerCallDcm_MainFunction_ConditionCheckRead_DataServices_Read_Vehicle_Security_related_events_Brute_Force_UDS_0x27_23118d0a: operation=DataServices_Read_Vehicle_Security_related_events_Brute_Force_UDS_0x27_servic_Event_occurance_time_Year_1.ConditionCheckRead
            OpServerCallDcm_MainFunction_ReadData_DataServices_Read_Vehicle_Security_related_events_Brute_Force_UDS_0x27_servic_Bru_b7ddcbdf: operation=DataServices_Read_Vehicle_Security_related_events_Brute_Force_UDS_0x27_servic_Brute_Force_UDS_0x27_service_Event_occurr_0DEE2FAA.ReadData
            OpServerCallDcm_MainFunction_ConditionCheckRead_DataServices_Read_Vehicle_Security_related_events_Brute_Force_UDS_0x27_ae4611ab: operation=DataServices_Read_Vehicle_Security_related_events_Brute_Force_UDS_0x27_servic_Brute_Force_UDS_0x27_service_Event_occurr_0DEE2FAA.ConditionCheckRead
            OpServerCallDcm_MainFunction_ReadData_DataServices_Read_Vehicle_Security_related_events_Brute_Force_UDS_0x27_servic_Eve_1eb9f5f0: operation=DataServices_Read_Vehicle_Security_related_events_Brute_Force_UDS_0x27_servic_Event_occurance_time_Day_1.ReadData
            OpServerCallDcm_MainFunction_ConditionCheckRead_DataServices_Read_Vehicle_Security_related_events_Brute_Force_UDS_0x27_4887e5fc: operation=DataServices_Read_Vehicle_Security_related_events_Brute_Force_UDS_0x27_servic_Event_occurance_time_Day_1.ConditionCheckRead
            OpServerCallDcm_MainFunction_ReadData_DataServices_Read_Vehicle_Security_related_events_Brute_Force_UDS_0x27_servic_Eve_87b0a44a: operation=DataServices_Read_Vehicle_Security_related_events_Brute_Force_UDS_0x27_servic_Event_occurance_time_Day_2.ReadData
            OpServerCallDcm_MainFunction_ConditionCheckRead_DataServices_Read_Vehicle_Security_related_events_Brute_Force_UDS_0x27_d18eb446: operation=DataServices_Read_Vehicle_Security_related_events_Brute_Force_UDS_0x27_servic_Event_occurance_time_Day_2.ConditionCheckRead
            OpServerCallDcm_MainFunction_ReadData_DataServices_Read_Vehicle_Security_related_events_Brute_Force_UDS_0x27_servic_Bru_c2454660: operation=DataServices_Read_Vehicle_Security_related_events_Brute_Force_UDS_0x27_servic_Brute_Force_UDS_0x27_service_4.ReadData
            OpServerCallDcm_MainFunction_ConditionCheckRead_DataServices_Read_Vehicle_Security_related_events_Brute_Force_UDS_0x27_5778b514: operation=DataServices_Read_Vehicle_Security_related_events_Brute_Force_UDS_0x27_servic_Brute_Force_UDS_0x27_service_4.ConditionCheckRead
            OpServerCallDcm_MainFunction_ReadData_DataServices_Read_Vehicle_Security_related_events_Brute_Force_UDS_0x27_servic_Eve_f0b794dc: operation=DataServices_Read_Vehicle_Security_related_events_Brute_Force_UDS_0x27_servic_Event_occurance_time_Day_3.ReadData
            OpServerCallDcm_MainFunction_ConditionCheckRead_DataServices_Read_Vehicle_Security_related_events_Brute_Force_UDS_0x27_a68984d0: operation=DataServices_Read_Vehicle_Security_related_events_Brute_Force_UDS_0x27_servic_Event_occurance_time_Day_3.ConditionCheckRead
            OpServerCallDcm_MainFunction_ReadData_DataServices_Read_Vehicle_Security_related_events_Brute_Force_UDS_0x27_servic_Eve_6ed3017f: operation=DataServices_Read_Vehicle_Security_related_events_Brute_Force_UDS_0x27_servic_Event_occurance_time_Day_4.ReadData
            OpServerCallDcm_MainFunction_ConditionCheckRead_DataServices_Read_Vehicle_Security_related_events_Brute_Force_UDS_0x27_38ed1173: operation=DataServices_Read_Vehicle_Security_related_events_Brute_Force_UDS_0x27_servic_Event_occurance_time_Day_4.ConditionCheckRead
            OpServerCallDcm_MainFunction_ReadData_DataServices_Read_Vehicle_Security_related_events_Brute_Force_UDS_0x27_servic_Bru_5c21d3c3: operation=DataServices_Read_Vehicle_Security_related_events_Brute_Force_UDS_0x27_servic_Brute_Force_UDS_0x27_service_3.ReadData
            OpServerCallDcm_MainFunction_ConditionCheckRead_DataServices_Read_Vehicle_Security_related_events_Brute_Force_UDS_0x27_c91c20b7: operation=DataServices_Read_Vehicle_Security_related_events_Brute_Force_UDS_0x27_servic_Brute_Force_UDS_0x27_service_3.ConditionCheckRead
            OpServerCallDcm_MainFunction_ReadData_DataServices_Read_Vehicle_Security_related_events_Brute_Force_UDS_0x27_servic_Eve_19d431e9: operation=DataServices_Read_Vehicle_Security_related_events_Brute_Force_UDS_0x27_servic_Event_occurance_time_Day_5.ReadData
            OpServerCallDcm_MainFunction_ConditionCheckRead_DataServices_Read_Vehicle_Security_related_events_Brute_Force_UDS_0x27_4fea21e5: operation=DataServices_Read_Vehicle_Security_related_events_Brute_Force_UDS_0x27_servic_Event_occurance_time_Day_5.ConditionCheckRead
            OpServerCallDcm_MainFunction_ReadData_DataServices_Read_Vehicle_Security_related_events_Brute_Force_UDS_0x27_servic_Eve_044aa942: operation=DataServices_Read_Vehicle_Security_related_events_Brute_Force_UDS_0x27_servic_Event_occurance_time_Month_2.ReadData
            OpServerCallDcm_MainFunction_ConditionCheckRead_DataServices_Read_Vehicle_Security_related_events_Brute_Force_UDS_0x27_b548a014: operation=DataServices_Read_Vehicle_Security_related_events_Brute_Force_UDS_0x27_servic_Event_occurance_time_Month_2.ConditionCheckRead
            OpServerCallDcm_MainFunction_ReadData_DataServices_Read_Vehicle_Security_related_events_Brute_Force_UDS_0x27_servic_Bru_b54276f6: operation=DataServices_Read_Vehicle_Security_related_events_Brute_Force_UDS_0x27_servic_Brute_Force_UDS_0x27_service_5.ReadData
            OpServerCallDcm_MainFunction_ConditionCheckRead_DataServices_Read_Vehicle_Security_related_events_Brute_Force_UDS_0x27_207f8582: operation=DataServices_Read_Vehicle_Security_related_events_Brute_Force_UDS_0x27_servic_Brute_Force_UDS_0x27_service_5.ConditionCheckRead
            OpServerCallDcm_MainFunction_ReadData_DataServices_Read_Vehicle_Security_related_events_Brute_Force_UDS_0x27_servic_Eve_9d43f8f8: operation=DataServices_Read_Vehicle_Security_related_events_Brute_Force_UDS_0x27_servic_Event_occurance_time_Month_1.ReadData
            OpServerCallDcm_MainFunction_ConditionCheckRead_DataServices_Read_Vehicle_Security_related_events_Brute_Force_UDS_0x27_2c41f1ae: operation=DataServices_Read_Vehicle_Security_related_events_Brute_Force_UDS_0x27_servic_Event_occurance_time_Month_1.ConditionCheckRead
            OpServerCallDcm_MainFunction_ReadData_DataServices_Read_Vehicle_Security_related_events_Brute_Force_UDS_0x27_servic_Eve_ed290c77: operation=DataServices_Read_Vehicle_Security_related_events_Brute_Force_UDS_0x27_servic_Event_occurance_time_Month_4.ReadData
            OpServerCallDcm_MainFunction_ConditionCheckRead_DataServices_Read_Vehicle_Security_related_events_Brute_Force_UDS_0x27_5c2b0521: operation=DataServices_Read_Vehicle_Security_related_events_Brute_Force_UDS_0x27_servic_Event_occurance_time_Month_4.ConditionCheckRead
            OpServerCallDcm_MainFunction_ReadData_DataServices_Read_Vehicle_Security_related_events_Brute_Force_UDS_0x27_servic_Eve_734d99d4: operation=DataServices_Read_Vehicle_Security_related_events_Brute_Force_UDS_0x27_servic_Event_occurance_time_Month_3.ReadData
            OpServerCallDcm_MainFunction_ConditionCheckRead_DataServices_Read_Vehicle_Security_related_events_Brute_Force_UDS_0x27_c24f9082: operation=DataServices_Read_Vehicle_Security_related_events_Brute_Force_UDS_0x27_servic_Event_occurance_time_Month_3.ConditionCheckRead
            OpServerCallDcm_MainFunction_ReadData_DataServices_Read_Vehicle_Security_related_events_Brute_Force_UDS_0x27_servic_Eve_9a2e3ce1: operation=DataServices_Read_Vehicle_Security_related_events_Brute_Force_UDS_0x27_servic_Event_occurance_time_Month_5.ReadData
            OpServerCallDcm_MainFunction_ConditionCheckRead_DataServices_Read_Vehicle_Security_related_events_Brute_Force_UDS_0x27_2b2c35b7: operation=DataServices_Read_Vehicle_Security_related_events_Brute_Force_UDS_0x27_servic_Event_occurance_time_Month_5.ConditionCheckRead
            OpServerCallDcm_MainFunction_ReadData_DataServices_Read_Vehicle_Security_related_events_Brute_Force_UDS_0x27_servic_Eve_5a9b0bbe: operation=DataServices_Read_Vehicle_Security_related_events_Brute_Force_UDS_0x27_servic_Event_occurance_time_Year_4.ReadData
            OpServerCallDcm_MainFunction_ConditionCheckRead_DataServices_Read_Vehicle_Security_related_events_Brute_Force_UDS_0x27_537b7985: operation=DataServices_Read_Vehicle_Security_related_events_Brute_Force_UDS_0x27_servic_Event_occurance_time_Year_4.ConditionCheckRead
            OpServerCallDcm_MainFunction_ReadData_DataServices_Read_Vehicle_Security_related_events_Brute_Force_UDS_0x27_servic_Eve_2d9c3b28: operation=DataServices_Read_Vehicle_Security_related_events_Brute_Force_UDS_0x27_servic_Event_occurance_time_Year_5.ReadData
            OpServerCallDcm_MainFunction_ConditionCheckRead_DataServices_Read_Vehicle_Security_related_events_Brute_Force_UDS_0x27_247c4913: operation=DataServices_Read_Vehicle_Security_related_events_Brute_Force_UDS_0x27_servic_Event_occurance_time_Year_5.ConditionCheckRead
            OpServerCallDcm_MainFunction_ReadData_DataServices_Read_Vehicle_Security_related_events_Brute_Force_UDS_0x27_servic_Eve_b3f8ae8b: operation=DataServices_Read_Vehicle_Security_related_events_Brute_Force_UDS_0x27_servic_Event_occurance_time_Year_2.ReadData
            OpServerCallDcm_MainFunction_ConditionCheckRead_DataServices_Read_Vehicle_Security_related_events_Brute_Force_UDS_0x27_ba18dcb0: operation=DataServices_Read_Vehicle_Security_related_events_Brute_Force_UDS_0x27_servic_Event_occurance_time_Year_2.ConditionCheckRead
            OpServerCallDcm_MainFunction_ReadData_DataServices_Read_Vehicle_Security_related_events_Brute_Force_UDS_0x27_servic_Eve_c4ff9e1d: operation=DataServices_Read_Vehicle_Security_related_events_Brute_Force_UDS_0x27_servic_Event_occurance_time_Year_3.ReadData
            OpServerCallDcm_MainFunction_ConditionCheckRead_DataServices_Read_Vehicle_Security_related_events_Brute_Force_UDS_0x27_cd1fec26: operation=DataServices_Read_Vehicle_Security_related_events_Brute_Force_UDS_0x27_servic_Event_occurance_time_Year_3.ConditionCheckRead
            OpServerCallDcm_MainFunction_ReadData_DataServices_Read_Vehicle_Security_related_events_Brute_Force_UDS_0x27_servic_Bru_2b26e355: operation=DataServices_Read_Vehicle_Security_related_events_Brute_Force_UDS_0x27_servic_Brute_Force_UDS_0x27_service_2.ReadData
            OpServerCallDcm_MainFunction_ConditionCheckRead_DataServices_Read_Vehicle_Security_related_events_Brute_Force_UDS_0x27_be1b1021: operation=DataServices_Read_Vehicle_Security_related_events_Brute_Force_UDS_0x27_servic_Brute_Force_UDS_0x27_service_2.ConditionCheckRead
            OpServerCallDcm_MainFunction_ReadData_DataServices_Read_Vehicle_Security_related_events_Brute_Force_UDS_0x27_servic_Bru_b22fb2ef: operation=DataServices_Read_Vehicle_Security_related_events_Brute_Force_UDS_0x27_servic_Brute_Force_UDS_0x27_service_1.ReadData
            OpServerCallDcm_MainFunction_ConditionCheckRead_DataServices_Read_Vehicle_Security_related_events_Brute_Force_UDS_0x27_2712419b: operation=DataServices_Read_Vehicle_Security_related_events_Brute_Force_UDS_0x27_servic_Brute_Force_UDS_0x27_service_1.ConditionCheckRead
            OpServerCallDcm_MainFunction_ReadData_DataServices_Driver_Mode_Driver_Mode: operation=DataServices_Driver_Mode_Driver_Mode.ReadData
            OpServerCallDcm_MainFunction_ConditionCheckRead_DataServices_Driver_Mode_Driver_Mode: operation=DataServices_Driver_Mode_Driver_Mode.ConditionCheckRead
            OpServerCallDcm_MainFunction_ReadData_DataServices_Battery_Voltage_Battery_Voltage: operation=DataServices_Battery_Voltage_Battery_Voltage.ReadData
            OpServerCallDcm_MainFunction_ConditionCheckRead_DataServices_Battery_Voltage_Battery_Voltage: operation=DataServices_Battery_Voltage_Battery_Voltage.ConditionCheckRead
            OpServerCallDcm_MainFunction_ReadData_DataServices_Read_Write_coding_data_string_CDS_CDS_Short_VIN_High_Byte_7: operation=DataServices_Read_Write_coding_data_string_CDS_CDS_Short_VIN_High_Byte_7.ReadData
            OpServerCallDcm_MainFunction_ConditionCheckRead_DataServices_Read_Write_coding_data_string_CDS_CDS_Short_VIN_High_Byte_7: operation=DataServices_Read_Write_coding_data_string_CDS_CDS_Short_VIN_High_Byte_7.ConditionCheckRead
            OpServerCallDcm_MainFunction_WriteData_DataServices_Read_Write_coding_data_string_CDS_CDS_Short_VIN_High_Byte_7: operation=DataServices_Read_Write_coding_data_string_CDS_CDS_Short_VIN_High_Byte_7.WriteData
            OpServerCallDcm_MainFunction_ReadData_DataServices_Read_Write_coding_data_string_CDS_CDS_CRC: operation=DataServices_Read_Write_coding_data_string_CDS_CDS_CRC.ReadData
            OpServerCallDcm_MainFunction_ConditionCheckRead_DataServices_Read_Write_coding_data_string_CDS_CDS_CRC: operation=DataServices_Read_Write_coding_data_string_CDS_CDS_CRC.ConditionCheckRead
            OpServerCallDcm_MainFunction_WriteData_DataServices_Read_Write_coding_data_string_CDS_CDS_CRC: operation=DataServices_Read_Write_coding_data_string_CDS_CDS_CRC.WriteData
            OpServerCallDcm_MainFunction_ReadData_DataServices_Read_Write_coding_data_string_CDS_CDS_Format_Byte_High_Byte_0: operation=DataServices_Read_Write_coding_data_string_CDS_CDS_Format_Byte_High_Byte_0.ReadData
            OpServerCallDcm_MainFunction_ConditionCheckRead_DataServices_Read_Write_coding_data_string_CDS_CDS_Format_Byte_High_Byte_0: operation=DataServices_Read_Write_coding_data_string_CDS_CDS_Format_Byte_High_Byte_0.ConditionCheckRead
            OpServerCallDcm_MainFunction_WriteData_DataServices_Read_Write_coding_data_string_CDS_CDS_Format_Byte_High_Byte_0: operation=DataServices_Read_Write_coding_data_string_CDS_CDS_Format_Byte_High_Byte_0.WriteData
            OpServerCallDcm_MainFunction_ReadData_DataServices_Read_Write_coding_data_string_CDS_CDS_Format_Byte_High_Byte_1: operation=DataServices_Read_Write_coding_data_string_CDS_CDS_Format_Byte_High_Byte_1.ReadData
            OpServerCallDcm_MainFunction_ConditionCheckRead_DataServices_Read_Write_coding_data_string_CDS_CDS_Format_Byte_High_Byte_1: operation=DataServices_Read_Write_coding_data_string_CDS_CDS_Format_Byte_High_Byte_1.ConditionCheckRead
            OpServerCallDcm_MainFunction_WriteData_DataServices_Read_Write_coding_data_string_CDS_CDS_Format_Byte_High_Byte_1: operation=DataServices_Read_Write_coding_data_string_CDS_CDS_Format_Byte_High_Byte_1.WriteData
            OpServerCallDcm_MainFunction_ReadData_DataServices_Read_Write_coding_data_string_CDS_Reserved2: operation=DataServices_Read_Write_coding_data_string_CDS_Reserved2.ReadData
            OpServerCallDcm_MainFunction_ConditionCheckRead_DataServices_Read_Write_coding_data_string_CDS_Reserved2: operation=DataServices_Read_Write_coding_data_string_CDS_Reserved2.ConditionCheckRead
            OpServerCallDcm_MainFunction_WriteData_DataServices_Read_Write_coding_data_string_CDS_Reserved2: operation=DataServices_Read_Write_coding_data_string_CDS_Reserved2.WriteData
            OpServerCallDcm_MainFunction_ReadData_DataServices_Read_Write_coding_data_string_CDS_Version_Byte_0: operation=DataServices_Read_Write_coding_data_string_CDS_Version_Byte_0.ReadData
            OpServerCallDcm_MainFunction_ConditionCheckRead_DataServices_Read_Write_coding_data_string_CDS_Version_Byte_0: operation=DataServices_Read_Write_coding_data_string_CDS_Version_Byte_0.ConditionCheckRead
            OpServerCallDcm_MainFunction_WriteData_DataServices_Read_Write_coding_data_string_CDS_Version_Byte_0: operation=DataServices_Read_Write_coding_data_string_CDS_Version_Byte_0.WriteData
            OpServerCallDcm_MainFunction_ReadData_DataServices_Read_Write_coding_data_string_CDS_Reserved1: operation=DataServices_Read_Write_coding_data_string_CDS_Reserved1.ReadData
            OpServerCallDcm_MainFunction_ConditionCheckRead_DataServices_Read_Write_coding_data_string_CDS_Reserved1: operation=DataServices_Read_Write_coding_data_string_CDS_Reserved1.ConditionCheckRead
            OpServerCallDcm_MainFunction_WriteData_DataServices_Read_Write_coding_data_string_CDS_Reserved1: operation=DataServices_Read_Write_coding_data_string_CDS_Reserved1.WriteData
            OpServerCallDcm_MainFunction_ReadData_DataServices_Read_Write_coding_data_string_CDS_Reserved3: operation=DataServices_Read_Write_coding_data_string_CDS_Reserved3.ReadData
            OpServerCallDcm_MainFunction_ConditionCheckRead_DataServices_Read_Write_coding_data_string_CDS_Reserved3: operation=DataServices_Read_Write_coding_data_string_CDS_Reserved3.ConditionCheckRead
            OpServerCallDcm_MainFunction_WriteData_DataServices_Read_Write_coding_data_string_CDS_Reserved3: operation=DataServices_Read_Write_coding_data_string_CDS_Reserved3.WriteData
            OpServerCallDcm_MainFunction_ReadData_DataServices_Read_Write_coding_data_string_CDS_Version_Byte_1: operation=DataServices_Read_Write_coding_data_string_CDS_Version_Byte_1.ReadData
            OpServerCallDcm_MainFunction_ConditionCheckRead_DataServices_Read_Write_coding_data_string_CDS_Version_Byte_1: operation=DataServices_Read_Write_coding_data_string_CDS_Version_Byte_1.ConditionCheckRead
            OpServerCallDcm_MainFunction_WriteData_DataServices_Read_Write_coding_data_string_CDS_Version_Byte_1: operation=DataServices_Read_Write_coding_data_string_CDS_Version_Byte_1.WriteData
            OpServerCallDcm_MainFunction_ReadData_DataServices_Read_Write_coding_data_string_CDS_CDS_Short_VIN_High_Byte_4: operation=DataServices_Read_Write_coding_data_string_CDS_CDS_Short_VIN_High_Byte_4.ReadData
            OpServerCallDcm_MainFunction_ConditionCheckRead_DataServices_Read_Write_coding_data_string_CDS_CDS_Short_VIN_High_Byte_4: operation=DataServices_Read_Write_coding_data_string_CDS_CDS_Short_VIN_High_Byte_4.ConditionCheckRead
            OpServerCallDcm_MainFunction_WriteData_DataServices_Read_Write_coding_data_string_CDS_CDS_Short_VIN_High_Byte_4: operation=DataServices_Read_Write_coding_data_string_CDS_CDS_Short_VIN_High_Byte_4.WriteData
            OpServerCallDcm_MainFunction_ReadData_DataServices_Read_Write_coding_data_string_CDS_Configuration: operation=DataServices_Read_Write_coding_data_string_CDS_Configuration.ReadData
            OpServerCallDcm_MainFunction_ConditionCheckRead_DataServices_Read_Write_coding_data_string_CDS_Configuration: operation=DataServices_Read_Write_coding_data_string_CDS_Configuration.ConditionCheckRead
            OpServerCallDcm_MainFunction_WriteData_DataServices_Read_Write_coding_data_string_CDS_Configuration: operation=DataServices_Read_Write_coding_data_string_CDS_Configuration.WriteData
            OpServerCallDcm_MainFunction_ReadData_DataServices_Read_Write_coding_data_string_CDS_CDS_Short_VIN_High_Byte_3: operation=DataServices_Read_Write_coding_data_string_CDS_CDS_Short_VIN_High_Byte_3.ReadData
            OpServerCallDcm_MainFunction_ConditionCheckRead_DataServices_Read_Write_coding_data_string_CDS_CDS_Short_VIN_High_Byte_3: operation=DataServices_Read_Write_coding_data_string_CDS_CDS_Short_VIN_High_Byte_3.ConditionCheckRead
            OpServerCallDcm_MainFunction_WriteData_DataServices_Read_Write_coding_data_string_CDS_CDS_Short_VIN_High_Byte_3: operation=DataServices_Read_Write_coding_data_string_CDS_CDS_Short_VIN_High_Byte_3.WriteData
            OpServerCallDcm_MainFunction_ReadData_DataServices_Read_Write_coding_data_string_CDS_CDS_Short_VIN_High_Byte_5: operation=DataServices_Read_Write_coding_data_string_CDS_CDS_Short_VIN_High_Byte_5.ReadData
            OpServerCallDcm_MainFunction_ConditionCheckRead_DataServices_Read_Write_coding_data_string_CDS_CDS_Short_VIN_High_Byte_5: operation=DataServices_Read_Write_coding_data_string_CDS_CDS_Short_VIN_High_Byte_5.ConditionCheckRead
            OpServerCallDcm_MainFunction_WriteData_DataServices_Read_Write_coding_data_string_CDS_CDS_Short_VIN_High_Byte_5: operation=DataServices_Read_Write_coding_data_string_CDS_CDS_Short_VIN_High_Byte_5.WriteData
            OpServerCallDcm_MainFunction_ReadData_DataServices_Read_Write_coding_data_string_CDS_CDS_Short_VIN_High_Byte_0: operation=DataServices_Read_Write_coding_data_string_CDS_CDS_Short_VIN_High_Byte_0.ReadData
            OpServerCallDcm_MainFunction_ConditionCheckRead_DataServices_Read_Write_coding_data_string_CDS_CDS_Short_VIN_High_Byte_0: operation=DataServices_Read_Write_coding_data_string_CDS_CDS_Short_VIN_High_Byte_0.ConditionCheckRead
            OpServerCallDcm_MainFunction_WriteData_DataServices_Read_Write_coding_data_string_CDS_CDS_Short_VIN_High_Byte_0: operation=DataServices_Read_Write_coding_data_string_CDS_CDS_Short_VIN_High_Byte_0.WriteData
            OpServerCallDcm_MainFunction_ReadData_DataServices_Read_Write_coding_data_string_CDS_CDS_Short_VIN_High_Byte_2: operation=DataServices_Read_Write_coding_data_string_CDS_CDS_Short_VIN_High_Byte_2.ReadData
            OpServerCallDcm_MainFunction_ConditionCheckRead_DataServices_Read_Write_coding_data_string_CDS_CDS_Short_VIN_High_Byte_2: operation=DataServices_Read_Write_coding_data_string_CDS_CDS_Short_VIN_High_Byte_2.ConditionCheckRead
            OpServerCallDcm_MainFunction_WriteData_DataServices_Read_Write_coding_data_string_CDS_CDS_Short_VIN_High_Byte_2: operation=DataServices_Read_Write_coding_data_string_CDS_CDS_Short_VIN_High_Byte_2.WriteData
            OpServerCallDcm_MainFunction_ReadData_DataServices_Read_Write_coding_data_string_CDS_CDS_Short_VIN_High_Byte_1: operation=DataServices_Read_Write_coding_data_string_CDS_CDS_Short_VIN_High_Byte_1.ReadData
            OpServerCallDcm_MainFunction_ConditionCheckRead_DataServices_Read_Write_coding_data_string_CDS_CDS_Short_VIN_High_Byte_1: operation=DataServices_Read_Write_coding_data_string_CDS_CDS_Short_VIN_High_Byte_1.ConditionCheckRead
            OpServerCallDcm_MainFunction_WriteData_DataServices_Read_Write_coding_data_string_CDS_CDS_Short_VIN_High_Byte_1: operation=DataServices_Read_Write_coding_data_string_CDS_CDS_Short_VIN_High_Byte_1.WriteData
            OpServerCallDcm_MainFunction_ReadData_DataServices_Last_service_date_Day: operation=DataServices_Last_service_date_Day.ReadData
            OpServerCallDcm_MainFunction_ConditionCheckRead_DataServices_Last_service_date_Day: operation=DataServices_Last_service_date_Day.ConditionCheckRead
            OpServerCallDcm_MainFunction_WriteData_DataServices_Last_service_date_Day: operation=DataServices_Last_service_date_Day.WriteData
            OpServerCallDcm_MainFunction_ReadData_DataServices_Last_service_date_Month: operation=DataServices_Last_service_date_Month.ReadData
            OpServerCallDcm_MainFunction_ConditionCheckRead_DataServices_Last_service_date_Month: operation=DataServices_Last_service_date_Month.ConditionCheckRead
            OpServerCallDcm_MainFunction_WriteData_DataServices_Last_service_date_Month: operation=DataServices_Last_service_date_Month.WriteData
            OpServerCallDcm_MainFunction_ReadData_DataServices_Last_service_date_Year: operation=DataServices_Last_service_date_Year.ReadData
            OpServerCallDcm_MainFunction_ConditionCheckRead_DataServices_Last_service_date_Year: operation=DataServices_Last_service_date_Year.ConditionCheckRead
            OpServerCallDcm_MainFunction_WriteData_DataServices_Last_service_date_Year: operation=DataServices_Last_service_date_Year.WriteData
            OpServerCallDcm_MainFunction_ReadData_DataServices_Date_And_Time_Date_And_Time_Minute: operation=DataServices_Date_And_Time_Date_And_Time_Minute.ReadData
            OpServerCallDcm_MainFunction_ConditionCheckRead_DataServices_Date_And_Time_Date_And_Time_Minute: operation=DataServices_Date_And_Time_Date_And_Time_Minute.ConditionCheckRead
            OpServerCallDcm_MainFunction_ReadData_DataServices_Date_And_Time_Date_And_Time_Hour: operation=DataServices_Date_And_Time_Date_And_Time_Hour.ReadData
            OpServerCallDcm_MainFunction_ConditionCheckRead_DataServices_Date_And_Time_Date_And_Time_Hour: operation=DataServices_Date_And_Time_Date_And_Time_Hour.ConditionCheckRead
            OpServerCallDcm_MainFunction_ReadData_DataServices_Date_And_Time_Date_And_Time_Year: operation=DataServices_Date_And_Time_Date_And_Time_Year.ReadData
            OpServerCallDcm_MainFunction_ConditionCheckRead_DataServices_Date_And_Time_Date_And_Time_Year: operation=DataServices_Date_And_Time_Date_And_Time_Year.ConditionCheckRead
            OpServerCallDcm_MainFunction_ReadData_DataServices_Date_And_Time_Date_And_Time_Second: operation=DataServices_Date_And_Time_Date_And_Time_Second.ReadData
            OpServerCallDcm_MainFunction_ConditionCheckRead_DataServices_Date_And_Time_Date_And_Time_Second: operation=DataServices_Date_And_Time_Date_And_Time_Second.ConditionCheckRead
            OpServerCallDcm_MainFunction_ReadData_DataServices_Date_And_Time_Date_And_Time_Month: operation=DataServices_Date_And_Time_Date_And_Time_Month.ReadData
            OpServerCallDcm_MainFunction_ConditionCheckRead_DataServices_Date_And_Time_Date_And_Time_Month: operation=DataServices_Date_And_Time_Date_And_Time_Month.ConditionCheckRead
            OpServerCallDcm_MainFunction_ReadData_DataServices_Date_And_Time_Date_And_Time_Day: operation=DataServices_Date_And_Time_Date_And_Time_Day.ReadData
            OpServerCallDcm_MainFunction_ConditionCheckRead_DataServices_Date_And_Time_Date_And_Time_Day: operation=DataServices_Date_And_Time_Date_And_Time_Day.ConditionCheckRead
            OpServerCallDcm_MainFunction_ReadData_DataServices_VCU_Torque_parameter_VCU_RegenTorqueCap: operation=DataServices_VCU_Torque_parameter_VCU_RegenTorqueCap.ReadData
            OpServerCallDcm_MainFunction_ConditionCheckRead_DataServices_VCU_Torque_parameter_VCU_RegenTorqueCap: operation=DataServices_VCU_Torque_parameter_VCU_RegenTorqueCap.ConditionCheckRead
            OpServerCallDcm_MainFunction_ReadData_DataServices_VCU_Torque_parameter_Torque_MaxAllowed: operation=DataServices_VCU_Torque_parameter_Torque_MaxAllowed.ReadData
            OpServerCallDcm_MainFunction_ConditionCheckRead_DataServices_VCU_Torque_parameter_Torque_MaxAllowed: operation=DataServices_VCU_Torque_parameter_Torque_MaxAllowed.ConditionCheckRead
            OpServerCallDcm_MainFunction_ReadData_DataServices_VCU_Torque_parameter_VCU_MCUDesiredTorque: operation=DataServices_VCU_Torque_parameter_VCU_MCUDesiredTorque.ReadData
            OpServerCallDcm_MainFunction_ConditionCheckRead_DataServices_VCU_Torque_parameter_VCU_MCUDesiredTorque: operation=DataServices_VCU_Torque_parameter_VCU_MCUDesiredTorque.ConditionCheckRead
            OpServerCallDcm_MainFunction_ReadData_DataServices_VCU_Torque_parameter_Torque_MinAllowed: operation=DataServices_VCU_Torque_parameter_Torque_MinAllowed.ReadData
            OpServerCallDcm_MainFunction_ConditionCheckRead_DataServices_VCU_Torque_parameter_Torque_MinAllowed: operation=DataServices_VCU_Torque_parameter_Torque_MinAllowed.ConditionCheckRead
            OpServerCallDcm_MainFunction_ReadData_DataServices_ECU_application_software_ASW_version_number_Major_release: operation=DataServices_ECU_application_software_ASW_version_number_Major_release.ReadData
            OpServerCallDcm_MainFunction_ConditionCheckRead_DataServices_ECU_application_software_ASW_version_number_Major_release: operation=DataServices_ECU_application_software_ASW_version_number_Major_release.ConditionCheckRead
            OpServerCallDcm_MainFunction_ReadData_DataServices_ECU_application_software_ASW_version_number_Minor_release: operation=DataServices_ECU_application_software_ASW_version_number_Minor_release.ReadData
            OpServerCallDcm_MainFunction_ConditionCheckRead_DataServices_ECU_application_software_ASW_version_number_Minor_release: operation=DataServices_ECU_application_software_ASW_version_number_Minor_release.ConditionCheckRead
            OpServerCallDcm_MainFunction_ReadData_DataServices_ECU_application_software_ASW_version_number_No_functional_content_change: operation=DataServices_ECU_application_software_ASW_version_number_No_functional_content_change.ReadData
            OpServerCallDcm_MainFunction_ConditionCheckRead_DataServices_ECU_application_software_ASW_version_number_No_functional_e01d7696: operation=DataServices_ECU_application_software_ASW_version_number_No_functional_content_change.ConditionCheckRead
            OpServerCallDcm_MainFunction_ReadData_DataServices_Read_Level3_OEM_Key_written_status_Read_Level3_OEM_Key_rewrite_counter: operation=DataServices_Read_Level3_OEM_Key_written_status_Read_Level3_OEM_Key_rewrite_counter.ReadData
            OpServerCallDcm_MainFunction_ConditionCheckRead_DataServices_Read_Level3_OEM_Key_written_status_Read_Level3_OEM_Key_rew_04bd4f00: operation=DataServices_Read_Level3_OEM_Key_written_status_Read_Level3_OEM_Key_rewrite_counter.ConditionCheckRead
            OpServerCallDcm_MainFunction_WriteData_DataServices_Write_Level1_OEM_Key_OEM_Key_Value: operation=DataServices_Write_Level1_OEM_Key_OEM_Key_Value.WriteData
            OpServerCallDcm_MainFunction_WriteData_DataServices_Write_Level1_OEM_Key_CRC: operation=DataServices_Write_Level1_OEM_Key_CRC.WriteData
            OpServerCallDcm_MainFunction_ReadData_DataServices_Read_Write_complete_VIN_World_Manufacturers_Identification: operation=DataServices_Read_Write_complete_VIN_World_Manufacturers_Identification.ReadData
            OpServerCallDcm_MainFunction_ConditionCheckRead_DataServices_Read_Write_complete_VIN_World_Manufacturers_Identification: operation=DataServices_Read_Write_complete_VIN_World_Manufacturers_Identification.ConditionCheckRead
            OpServerCallDcm_MainFunction_WriteData_DataServices_Read_Write_complete_VIN_World_Manufacturers_Identification: operation=DataServices_Read_Write_complete_VIN_World_Manufacturers_Identification.WriteData
            OpServerCallDcm_MainFunction_ReadData_DataServices_Read_Write_complete_VIN_Vehicle_Description_Section: operation=DataServices_Read_Write_complete_VIN_Vehicle_Description_Section.ReadData
            OpServerCallDcm_MainFunction_ConditionCheckRead_DataServices_Read_Write_complete_VIN_Vehicle_Description_Section: operation=DataServices_Read_Write_complete_VIN_Vehicle_Description_Section.ConditionCheckRead
            OpServerCallDcm_MainFunction_WriteData_DataServices_Read_Write_complete_VIN_Vehicle_Description_Section: operation=DataServices_Read_Write_complete_VIN_Vehicle_Description_Section.WriteData
            OpServerCallDcm_MainFunction_ReadData_DataServices_Read_Write_complete_VIN_Vehicle_Identification_Section: operation=DataServices_Read_Write_complete_VIN_Vehicle_Identification_Section.ReadData
            OpServerCallDcm_MainFunction_ConditionCheckRead_DataServices_Read_Write_complete_VIN_Vehicle_Identification_Section: operation=DataServices_Read_Write_complete_VIN_Vehicle_Identification_Section.ConditionCheckRead
            OpServerCallDcm_MainFunction_WriteData_DataServices_Read_Write_complete_VIN_Vehicle_Identification_Section: operation=DataServices_Read_Write_complete_VIN_Vehicle_Identification_Section.WriteData
        GetActiveProtocol: can-be-invoked-concurrently=true, symbol=Dcm_GetActiveProtocol
        GetSesCtrlType: can-be-invoked-concurrently=true, symbol=Dcm_GetSesCtrlType
        ResetToDefaultSession: can-be-invoked-concurrently=true, symbol=Dcm_ResetToDefaultSession
        GetSecurityLevel: can-be-invoked-concurrently=true, symbol=Dcm_GetSecurityLevel
        SetActiveDiagnostic: can-be-invoked-concurrently=true, symbol=Dcm_SetActiveDiagnostic
        GetRequestKind: can-be-invoked-concurrently=true, symbol=Dcm_GetRequestKind
  swc implementation DcmImplementation: programming-language=C, behavior=DcmInternalBehavior
